VERSION "HIPBNNNYNNNNNNNNNNNNNNNNNNNNNNNNNNNNNNNNNN/4/%%/4/'%**4NNN///"

NS_ :

BS_:

BU_: EXXOTEST__XXX

BO_ 2565799678 ACL: 8 EXXOTEST__XXX
 SG_ ArbitraryAddressCapable : 63|1@1+ (1,0) [0|1] ""  EXXOTEST__XXX
 SG_ IndustryGroup M : 60|3@1+ (1,0) [0|7] ""  EXXOTEST__XXX
 SG_ VehicleSystemInstance : 56|4@1+ (1,0) [0|15] ""  EXXOTEST__XXX
 SG_ Function : 40|8@1+ (1,0) [0|255] ""  EXXOTEST__XXX
 SG_ FunctionInstance : 35|5@1+ (1,0) [0|31] ""  EXXOTEST__XXX
 SG_ ECUInstance : 32|3@1+ (1,0) [0|7] ""  EXXOTEST__XXX
 SG_ ManufacturerCode : 21|11@1+ (1,0) [0|2047] ""  EXXOTEST__XXX
 SG_ IdentityNumber : 0|21@1+ (1,0) [0|2097152] ""  EXXOTEST__XXX
 SG_ VehicleSystem m0 : 49|7@1+ (1,0) [0|127] ""  EXXOTEST__XXX
 SG_ VehicleSystem5 m5 : 49|7@1+ (1,0) [0|127] ""  EXXOTEST__XXX
 SG_ VehicleSystem4 m4 : 49|7@1+ (1,0) [0|127] ""  EXXOTEST__XXX
 SG_ VehicleSystem3 m3 : 49|7@1+ (1,0) [0|127] ""  EXXOTEST__XXX
 SG_ VehicleSystem2 m2 : 49|7@1+ (1,0) [0|127] ""  EXXOTEST__XXX
 SG_ VehicleSystem1 m1 : 49|7@1+ (1,0) [0|127] ""  EXXOTEST__XXX

BO_ 2632711934 TPDT: 8 EXXOTEST__XXX
 SG_ SequenceNumber : 0|8@1+ (1,0) [0|255] ""  EXXOTEST__XXX

BO_ 2632777470 TPCM: 8 EXXOTEST__XXX
 SG_ TotalNumberOfPacketsEoMA m19 : 24|8@1+ (1,0) [0|255] ""  EXXOTEST__XXX
 SG_ TotalMessageSizeEoMA m19 : 8|16@1+ (1,0) [0|64255] "counts"  EXXOTEST__XXX
 SG_ TotalMessageSizeBAM m32 : 8|16@1+ (1,0) [0|64255] "counts"  EXXOTEST__XXX
 SG_ TotalNumberOfPacketsBAM m32 : 24|8@1+ (1,0) [0|255] ""  EXXOTEST__XXX
 SG_ ConnectionAbortReason m255 : 8|8@1+ (1,0) [0|255] ""  EXXOTEST__XXX
 SG_ NextPacketNumberToBeSent m17 : 16|8@1+ (1,0) [0|255] ""  EXXOTEST__XXX
 SG_ NumberOfPacketsThatCanBeSent m17 : 8|8@1+ (1,0) [0|255] ""  EXXOTEST__XXX
 SG_ PGNumber : 40|24@1+ (1,0) [0|16777200] ""  EXXOTEST__XXX
 SG_ MaximumNumberOfPackets m16 : 32|8@1+ (1,0) [0|255] ""  EXXOTEST__XXX
 SG_ TotalNumberOfPackets m16 : 24|8@1+ (1,0) [0|255] ""  EXXOTEST__XXX
 SG_ TotalMessageSize m16 : 8|16@1+ (1,0) [0|64255] "counts"  EXXOTEST__XXX
 SG_ ControlByte M : 0|8@1+ (1,0) [0|255] ""  EXXOTEST__XXX

BO_ 2565537534 RQST: 3 EXXOTEST__XXX
 SG_ ParameterGroupNumber : 0|24@1+ (1,0) [0|16777215] ""  EXXOTEST__XXX

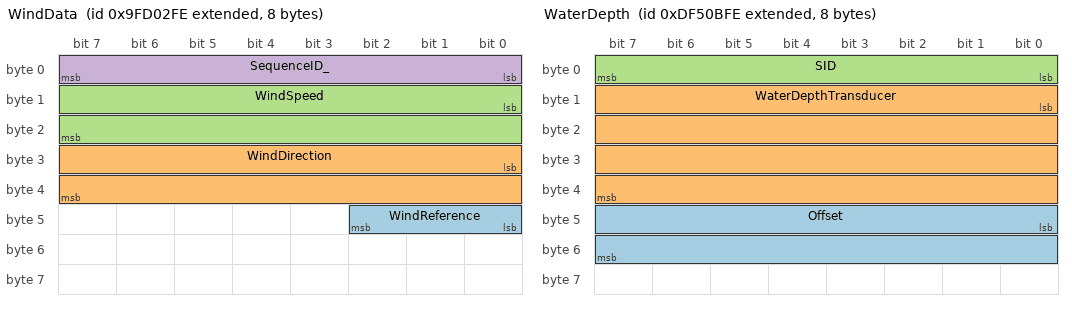
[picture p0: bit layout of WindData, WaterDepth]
BO_ 2315059966 WindData: 8 EXXOTEST__XXX
 SG_ WindReference : 40|3@1+ (1,0) [0|7] ""  EXXOTEST__XXX
 SG_ WindDirection : 24|16@1+ (0.0001,0) [0|6.28318] "rad"  EXXOTEST__XXX
 SG_ WindSpeed : 8|16@1+ (0.01,0) [0|655.32] "m/s"  EXXOTEST__XXX
 SG_ SequenceID_ : 0|8@1+ (1,0) [0|252] ""  EXXOTEST__XXX

BO_ 2381646846 WaterDepth: 8 EXXOTEST__XXX
 SG_ Offset : 40|16@1- (0.001,0) [-32.764|32.764] "m"  EXXOTEST__XXX
 SG_ WaterDepthTransducer : 8|32@1+ (0.01,0) [0|42950000] "m"  EXXOTEST__XXX
 SG_ SID : 0|8@1+ (1,0) [0|252] ""  EXXOTEST__XXX

BO_ 2315129598 VesselSpeedComponents: 12 EXXOTEST__XXX
 SG_ SternSpeedGroundreferenced : 80|16@1- (0.001,0) [-32.764|32.764] "m/s"  EXXOTEST__XXX
 SG_ SternSpeedWaterreferenced : 64|16@1- (0.001,0) [-32.764|32.764] "m/s"  EXXOTEST__XXX
 SG_ TransverseSpeedGroundreferenced : 48|16@1- (0.001,0) [-32.764|32.764] "m/s"  EXXOTEST__XXX
 SG_ LngtudinalSpeedGroundreferenced : 32|16@1- (0.001,0) [-32.764|32.764] "m/s"  EXXOTEST__XXX
 SG_ TransverseSpeedWaterreferenced : 16|16@1- (0.001,0) [-32.764|32.764] "m/s"  EXXOTEST__XXX
 SG_ LngitudinalSpeedWaterreferenced : 0|16@1- (0.001,0) [-32.764|32.764] "m/s"  EXXOTEST__XXX

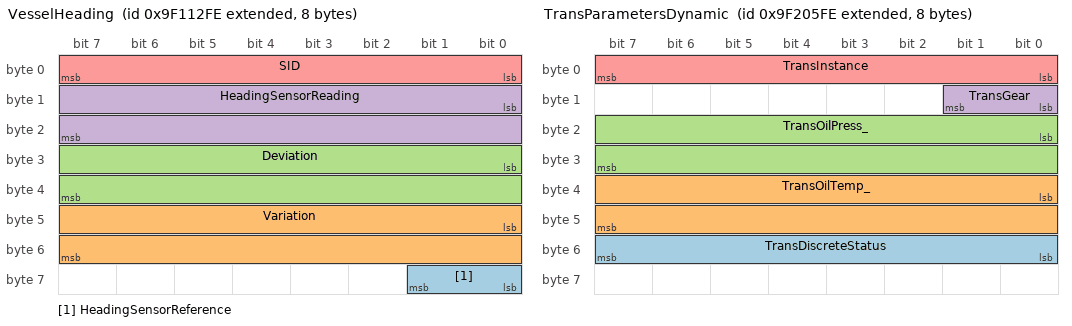
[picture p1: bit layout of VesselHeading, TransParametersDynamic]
BO_ 2314277630 VesselHeading: 8 EXXOTEST__XXX
 SG_ HeadingSensorReference : 56|2@1+ (1,0) [0|3] ""  EXXOTEST__XXX
 SG_ Variation : 40|16@1- (0.0001,0) [-3.14159|3.14159] "rad"  EXXOTEST__XXX
 SG_ Deviation : 24|16@1- (0.0001,0) [-3.14159|3.14159] "rad"  EXXOTEST__XXX
 SG_ HeadingSensorReading : 8|16@1+ (0.0001,0) [0|6.28318] "rad"  EXXOTEST__XXX
 SG_ SID : 0|8@1+ (1,0) [0|252] ""  EXXOTEST__XXX

BO_ 2583172606 UserDatumSettings: 40 EXXOTEST__XXX

BO_ 2515667198 TripParametersVessel: 14 EXXOTEST__XXX
 SG_ TripRunTime : 80|32@1+ (0.001,0) [0|4295000] "sec"  EXXOTEST__XXX
 SG_ EstFuelRemaining : 64|16@1+ (0.001,0) [0|65.532] "cu_m"  EXXOTEST__XXX
 SG_ DistanceToEmpty : 32|32@1+ (0.01,0) [0|42950000] "m"  EXXOTEST__XXX
 SG_ TimeToEmpty : 0|32@1+ (0.001,0) [0|4295000] "sec"  EXXOTEST__XXX

BO_ 2515667454 TripParametersEng: 9 EXXOTEST__XXX
 SG_ InstantaneousFuelEconomy : 56|16@1- (0.0001,0) [-3.2764|3.2764] "cu_m/hr"  EXXOTEST__XXX
 SG_ FuelRateEconomy : 40|16@1- (0.0001,0) [-3.2764|3.2764] "cu_m/hr"  EXXOTEST__XXX
 SG_ FuelRateAverage : 24|16@1- (0.0001,0) [-3.2764|3.2764] "cu_m/hr"  EXXOTEST__XXX
 SG_ TripFuelUsed : 8|16@1+ (0.001,0) [0|65.532] "cu_m"  EXXOTEST__XXX
 SG_ EngInstance : 0|8@1+ (1,0) [0|255] ""  EXXOTEST__XXX

BO_ 2314339838 TransParametersDynamic: 8 EXXOTEST__XXX
 SG_ TransDiscreteStatus : 48|8@1+ (1,0) [0|255] ""  EXXOTEST__XXX
 SG_ TransOilTemp_ : 32|16@1+ (0.1,0) [0|6553.2] "°K"  EXXOTEST__XXX
 SG_ TransOilPress_ : 16|16@1+ (100,0) [0|6553200] "Pa"  EXXOTEST__XXX
 SG_ TransGear : 8|2@1+ (1,0) [0|3] ""  EXXOTEST__XXX
 SG_ TransInstance : 0|8@1+ (1,0) [0|255] ""  EXXOTEST__XXX

BO_ 2314602750 TrackedTargetData: 28 EXXOTEST__XXX
 SG_ CPA : 112|32@1- (0.01,0) [-21470000|21470000] "m"  EXXOTEST__XXX
 SG_ Speed : 96|16@1+ (0.01,0) [0|655.32] "m/s"  EXXOTEST__XXX
 SG_ Course : 80|16@1+ (0.0001,0) [0|6.28318] "rad"  EXXOTEST__XXX
 SG_ Distance : 48|32@1- (0.01,0) [-21470000|21470000] "m"  EXXOTEST__XXX
 SG_ Bearing : 32|16@1+ (0.0001,0) [0|6.28318] "rad"  EXXOTEST__XXX
 SG_ BearingReference : 28|2@1+ (1,0) [0|3] ""  EXXOTEST__XXX
 SG_ TrackStatus : 24|4@1+ (1,0) [0|15] ""  EXXOTEST__XXX
 SG_ TargetID : 8|16@1+ (1,0) [0|65532] ""  EXXOTEST__XXX
 SG_ SequenceID_ : 0|8@1+ (1,0) [0|252] ""  EXXOTEST__XXX
 SG_ Name : 208|16@1+ (1,0) [0|255] ""  EXXOTEST__XXX
 SG_ UTCOfFix : 176|32@1+ (0.0001,0) [0|86401] "sec"  EXXOTEST__XXX
 SG_ TCPA : 144|32@1- (0.001,0) [-2148000|2148000] "sec"  EXXOTEST__XXX

BO_ 2650544894 RouteAndWPServiceWPListWPNamePos: 14 EXXOTEST__XXX
 SG_ WPName : 96|16@1+ (1,0) [0|255] "ASCII"  EXXOTEST__XXX
 SG_ WPID : 80|16@1+ (1,0) [0|65532] ""  EXXOTEST__XXX
 SG_ reserved : 64|16@1+ (1,0) [0|65532] ""  EXXOTEST__XXX
 SG_ DatabaseID : 48|16@1+ (1,0) [0|65532] ""  EXXOTEST__XXX
 SG_ NumberOfValidWPsInWPList : 32|16@1+ (1,0) [0|65532] ""  EXXOTEST__XXX
 SG_ nItems : 16|16@1+ (1,0) [0|65532] ""  EXXOTEST__XXX
 SG_ StartWPID : 0|16@1+ (1,0) [0|65532] ""  EXXOTEST__XXX

BO_ 2650544382 RouteAndWPServiceDatabaseComment: 11 EXXOTEST__XXX
 SG_ CommentText : 64|24@1+ (1,0) [0|255] ""  EXXOTEST__XXX
 SG_ DatabaseID : 48|16@1+ (1,0) [0|65532] ""  EXXOTEST__XXX
 SG_ NumberOfDatabasesWithComments : 32|16@1+ (1,0) [0|65532] ""  EXXOTEST__XXX
 SG_ nItems : 16|16@1+ (1,0) [0|65532] ""  EXXOTEST__XXX
 SG_ StartDatabaseID : 0|16@1+ (1,0) [0|65532] ""  EXXOTEST__XXX

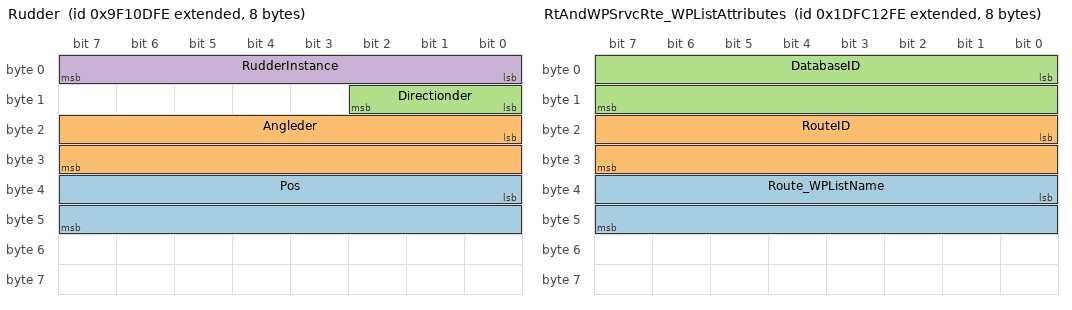
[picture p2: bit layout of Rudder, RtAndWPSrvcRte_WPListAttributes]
BO_ 2314276350 Rudder: 8 EXXOTEST__XXX
 SG_ Pos : 32|16@1- (0.0001,0) [-3.14159|3.14159] "rad"  EXXOTEST__XXX
 SG_ Angleder : 16|16@1- (0.0001,0) [-3.14159|3.14159] "rad"  EXXOTEST__XXX
 SG_ Directionder : 8|3@1+ (1,0) [0|7] ""  EXXOTEST__XXX
 SG_ RudderInstance : 0|8@1+ (1,0) [0|255] ""  EXXOTEST__XXX

BO_ 2650543614 RtAndWPSrvcXTELmtNvgationMethod: 15 EXXOTEST__XXX
 SG_ NavMethodInLegAfterWP : 112|2@1+ (1,0) [0|3] ""  EXXOTEST__XXX
 SG_ XTELimitInLegAfterWP : 96|16@1- (1,0) [-32764|32764] "m"  EXXOTEST__XXX
 SG_ RPS : 80|16@1+ (1,0) [0|65532] ""  EXXOTEST__XXX
 SG_ RouteID : 64|16@1+ (1,0) [0|65532] ""  EXXOTEST__XXX
 SG_ DatabaseID : 48|16@1+ (1,0) [0|65532] ""  EXXOTEST__XXX
 SG_ NmbrOfWypntsWthASpcfcXTELmtNvMth : 32|16@1+ (1,0) [0|65532] ""  EXXOTEST__XXX
 SG_ nItems : 16|16@1+ (1,0) [0|65532] ""  EXXOTEST__XXX
 SG_ StartRPS : 0|16@1+ (1,0) [0|65532] ""  EXXOTEST__XXX

BO_ 2650542846 RtAndWPSrvcRte_WPListAttributes: 8 EXXOTEST__XXX
 SG_ Route_WPListName : 32|16@1+ (1,0) [0|255] "ASCII"  EXXOTEST__XXX
 SG_ RouteID : 16|16@1+ (1,0) [0|65532] ""  EXXOTEST__XXX
 SG_ DatabaseID : 0|16@1+ (1,0) [0|65532] ""  EXXOTEST__XXX

BO_ 2650543870 RouteAndWPServiceWPComment: 15 EXXOTEST__XXX
 SG_ Comment : 96|24@1+ (1,0) [0|255] ""  EXXOTEST__XXX
 SG_ WPID_RPS : 80|16@1+ (1,0) [0|65532] ""  EXXOTEST__XXX
 SG_ RouteID : 64|16@1+ (1,0) [0|65532] ""  EXXOTEST__XXX
 SG_ DatabaseID : 48|16@1+ (1,0) [0|65532] ""  EXXOTEST__XXX
 SG_ NumberOfWPsWithComments : 32|16@1+ (1,0) [0|65532] ""  EXXOTEST__XXX
 SG_ nItems : 16|16@1+ (1,0) [0|65532] ""  EXXOTEST__XXX
 SG_ StartID : 0|16@1+ (1,0) [0|65532] ""  EXXOTEST__XXX

BO_ 2583300606 GNSSRAIMOutput: 15 EXXOTEST__XXX
 SG_ StdDeviationOfBias : 104|16@1- (0.01,0) [-327.64|327.64] "m"  EXXOTEST__XXX
 SG_ EstimateOfPseudorangeBias : 88|16@1- (0.01,0) [-327.64|327.64] "m"  EXXOTEST__XXX
 SG_ ProbabilityOfMissedDetection : 72|8@1- (1,0) [-124|124] "%"  EXXOTEST__XXX
 SG_ SVIDOfMostLikelyFailedSat : 64|8@1+ (1,0) [0|252] ""  EXXOTEST__XXX
 SG_ AltitudeExpectedError : 48|16@1- (0.01,0) [-327.64|327.64] "m"  EXXOTEST__XXX
 SG_ LongitudeExpectedError : 32|16@1- (0.01,0) [-327.64|327.64] "m"  EXXOTEST__XXX
 SG_ LatitudeExpectedError : 16|16@1- (0.01,0) [-327.64|327.64] "m"  EXXOTEST__XXX
 SG_ IntegrityFlag : 8|2@1+ (1,0) [0|3] ""  EXXOTEST__XXX
 SG_ SequenceID_ : 0|8@1+ (1,0) [0|252] ""  EXXOTEST__XXX

BO_ 2583299838 GNSSPseudorangeNoiseStatistics: 15 EXXOTEST__XXX
 SG_ STDOfAltError : 104|16@1+ (0.01,0) [0|655.32] "m"  EXXOTEST__XXX
 SG_ STDOfLonError : 88|16@1+ (0.01,0) [0|655.32] "m"  EXXOTEST__XXX
 SG_ STDOfLatError : 72|16@1+ (0.01,0) [0|655.32] "m"  EXXOTEST__XXX
 SG_ OrientationOfMajorAxis : 56|16@1+ (0.0001,0) [0|6.28318] "rad"  EXXOTEST__XXX
 SG_ STDOfMinorAxis : 40|16@1+ (0.01,0) [0|655.32] "m"  EXXOTEST__XXX
 SG_ STDOfMajorAxis : 24|16@1+ (0.01,0) [0|655.32] "m"  EXXOTEST__XXX
 SG_ RMSOfPosUncertainty : 8|16@1+ (0.01,0) [0|655.32] "m"  EXXOTEST__XXX
 SG_ SID : 0|8@1+ (1,0) [0|252] ""  EXXOTEST__XXX

BO_ 2583301118 GNSSPseudorangeErrorStatistics: 15 EXXOTEST__XXX
 SG_ StdDevAltitudeError : 104|16@1+ (0.01,0) [0|655.32] "m"  EXXOTEST__XXX
 SG_ StdDevLongitudeError : 88|16@1+ (0.01,0) [0|655.32] "m"  EXXOTEST__XXX
 SG_ StdDevLatitudeError : 72|16@1+ (0.01,0) [0|655.32] "m"  EXXOTEST__XXX
 SG_ OrientationOfErrorEllipse : 56|16@1+ (0.0001,0) [0|6.28318] "rad"  EXXOTEST__XXX
 SG_ StdDevMinorErrorEllipse : 40|16@1+ (0.01,0) [0|655.32] "m"  EXXOTEST__XXX
 SG_ StdDevMajorErrorEllipse : 24|16@1+ (0.01,0) [0|655.32] "m"  EXXOTEST__XXX
 SG_ RMSStdDevOfRangeInputs : 8|16@1+ (0.01,0) [0|655.32] "m"  EXXOTEST__XXX
 SG_ SequenceID_ : 0|8@1+ (1,0) [0|252] ""  EXXOTEST__XXX

BO_ 2381841918 GNSSPosData: 51 EXXOTEST__XXX
 SG_ AgeOfDGNSSReferenceStationN : 392|16@1+ (0.01,0) [0|655.32] "sec"  EXXOTEST__XXX
 SG_ ReferenceStationIDN : 380|12@1+ (1,0) [0|4095] ""  EXXOTEST__XXX
 SG_ ReferenceStationTypeN : 376|4@1+ (1,0) [0|15] ""  EXXOTEST__XXX
 SG_ AgeOfDGNSSCorrections1_ : 360|16@1+ (0.01,0) [0|655.32] "sec"  EXXOTEST__XXX
 SG_ ReferenceStationID1_ : 348|12@1+ (1,0) [0|4095] ""  EXXOTEST__XXX
 SG_ ReferenceStationType1 : 344|4@1+ (1,0) [0|15] ""  EXXOTEST__XXX
 SG_ NumberOfReferenceStations_ : 336|8@1+ (1,0) [0|252] ""  EXXOTEST__XXX
 SG_ GeoidalSeparation_ : 304|32@1- (0.01,0) [-21470000|21470000] "m"  EXXOTEST__XXX
 SG_ PDOP_ : 288|16@1- (0.01,0) [-327.64|327.64] ""  EXXOTEST__XXX
 SG_ HDOP_ : 272|16@1- (0.01,0) [-327.64|327.64] ""  EXXOTEST__XXX
 SG_ NumberOfSVs_ : 264|8@1+ (1,0) [0|252] ""  EXXOTEST__XXX
 SG_ Integrity : 256|2@1+ (1,0) [0|3] ""  EXXOTEST__XXX
 SG_ MethodGNSS : 252|4@1+ (1,0) [0|15] ""  EXXOTEST__XXX
 SG_ TypeOfSystem_ : 248|4@1+ (1,0) [0|15] ""  EXXOTEST__XXX
 SG_ Altitude_high : 216|32@1- (4294.967296,0) [-9223000000000|9223000000000] "m"  EXXOTEST__XXX
 SG_ Altitude_low : 184|32@1+ (1E-06,0) [0|4294.967295] "m"  EXXOTEST__XXX
 SG_ Longitude_high : 152|32@1- (1,0) [-180|180] "deg"  EXXOTEST__XXX
 SG_ Longitude_low : 120|32@1+ (1,0) [0|0] "deg"  EXXOTEST__XXX
 SG_ Latitude_high : 88|32@1- (1,0) [-90|90] "deg"  EXXOTEST__XXX
 SG_ Latitude_low : 56|32@1+ (1,0) [0|0] "deg"  EXXOTEST__XXX
 SG_ PosTime : 24|32@1+ (0.0001,0) [0|86401] "sec"  EXXOTEST__XXX
 SG_ PosDate : 8|16@1+ (1,0) [0|65532] "day"  EXXOTEST__XXX
 SG_ SID : 0|8@1+ (1,0) [0|252] ""  EXXOTEST__XXX

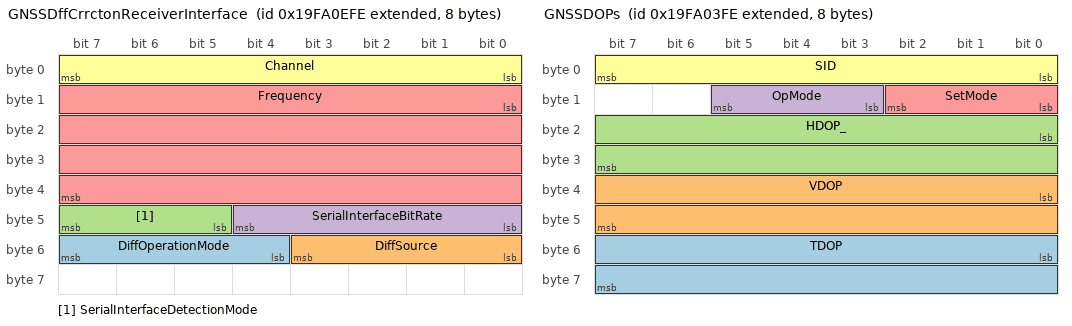
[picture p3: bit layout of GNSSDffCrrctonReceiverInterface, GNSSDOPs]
BO_ 2583301886 GNSSDffCrrctonReceiverInterface: 8 EXXOTEST__XXX
 SG_ DiffOperationMode : 52|4@1+ (1,0) [0|15] ""  EXXOTEST__XXX
 SG_ DiffSource : 48|4@1+ (1,0) [0|15] ""  EXXOTEST__XXX
 SG_ SerialInterfaceDetectionMode : 45|3@1+ (1,0) [0|7] ""  EXXOTEST__XXX
 SG_ SerialInterfaceBitRate : 40|5@1+ (1,0) [0|31] ""  EXXOTEST__XXX
 SG_ Frequency : 8|32@1+ (10,0) [0|327040] "Hz"  EXXOTEST__XXX
 SG_ Channel : 0|8@1+ (1,0) [0|252] ""  EXXOTEST__XXX

BO_ 2583302142 GNSSDffCorrectionReceiverSignal: 21 EXXOTEST__XXX
 SG_ SatelliteServiceIDNo : 147|16@1+ (1,0) [0|65535] ""  EXXOTEST__XXX
 SG_ TimeSinceLastSatDiffSync : 131|16@1+ (0.01,0) [0|655.32] "sec"  EXXOTEST__XXX
 SG_ DiffSource : 127|4@1+ (1,0) [0|15] ""  EXXOTEST__XXX
 SG_ UsedAsCorrectionSource : 123|2@1+ (1,0) [0|3] ""  EXXOTEST__XXX
 SG_ DiffSignalDetectionMode : 117|6@1+ (1,0) [0|63] ""  EXXOTEST__XXX
 SG_ DiffSignalBitRate : 112|5@1+ (1,0) [0|31] ""  EXXOTEST__XXX
 SG_ StationID : 100|12@1+ (1,0) [0|4095] ""  EXXOTEST__XXX
 SG_ StationType : 96|4@1+ (1,0) [0|15] ""  EXXOTEST__XXX
 SG_ Frequency : 64|32@1+ (10,0) [0|327040] "Hz"  EXXOTEST__XXX
 SG_ SignalSNR : 48|16@1- (0.01,0) [-327.64|327.64] "dB"  EXXOTEST__XXX
 SG_ SignalStrength : 16|32@1- (0.01,0) [-327.64|327.64] "dB_re_uV/m"  EXXOTEST__XXX
 SG_ Channel : 8|8@1+ (1,0) [0|252] ""  EXXOTEST__XXX
 SG_ SID : 0|8@1+ (1,0) [0|252] ""  EXXOTEST__XXX

BO_ 2583299070 GNSSDOPs: 8 EXXOTEST__XXX
 SG_ TDOP : 48|16@1- (0.01,0) [-327.64|327.64] ""  EXXOTEST__XXX
 SG_ VDOP : 32|16@1- (0.01,0) [-327.64|327.64] ""  EXXOTEST__XXX
 SG_ HDOP_ : 16|16@1- (0.01,0) [-327.64|327.64] ""  EXXOTEST__XXX
 SG_ OpMode : 11|3@1+ (1,0) [0|7] ""  EXXOTEST__XXX
 SG_ SetMode : 8|3@1+ (1,0) [0|7] ""  EXXOTEST__XXX
 SG_ SID : 0|8@1+ (1,0) [0|252] ""  EXXOTEST__XXX

BO_ 2583298814 GNSSCtrlStatus: 16 EXXOTEST__XXX
 SG_ UseAntennaAltitudeFor2DMode : 120|2@1+ (1,0) [0|3] ""  EXXOTEST__XXX
 SG_ AntennaAltitudeFor2DMode : 88|32@1- (0.01,0) [-21470000|21470000] "m"  EXXOTEST__XXX
 SG_ MaxCorrectionAge : 72|16@1+ (0.01,0) [0|655.32] "sec"  EXXOTEST__XXX
 SG_ Pos_VelocityFilter : 70|2@1+ (1,0) [0|3] ""  EXXOTEST__XXX
 SG_ DGNSSMode : 67|3@1+ (1,0) [0|7] ""  EXXOTEST__XXX
 SG_ GNSSMode : 64|3@1+ (1,0) [0|7] ""  EXXOTEST__XXX
 SG_ SNRMask : 48|16@1- (0.01,0) [-327.64|327.64] "dB"  EXXOTEST__XXX
 SG_ PDOPSwitch : 32|16@1- (0.01,0) [-327.64|327.64] ""  EXXOTEST__XXX
 SG_ PDOPMask : 16|16@1- (0.01,0) [-327.64|327.64] ""  EXXOTEST__XXX
 SG_ SVElevationMask : 0|16@1- (0.0001,0) [-3.14159|3.14159] "rad"  EXXOTEST__XXX

BO_ 2583303422 GLONASSAlmanacData: 26 EXXOTEST__XXX
 SG_ tnA2 : 196|12@1+ (1,0) [0|4095] ""  EXXOTEST__XXX
 SG_ tcA : 168|28@1+ (1,0) [0|268435455] ""  EXXOTEST__XXX
 SG_ inA : 144|24@1+ (1,0) [0|16777215] ""  EXXOTEST__XXX
 SG_ nA3 : 120|24@1+ (1,0) [0|16777215] ""  EXXOTEST__XXX
 SG_ tnA : 96|24@1+ (1,0) [0|16777215] ""  EXXOTEST__XXX
 SG_ TnA : 72|24@1+ (1,0) [0|16777215] ""  EXXOTEST__XXX
 SG_ nA2 : 56|16@1+ (1,0) [0|65535] ""  EXXOTEST__XXX
 SG_ DOT : 48|8@1+ (1,0) [0|255] ""  EXXOTEST__XXX
 SG_ nA : 32|16@1+ (1,0) [0|65535] ""  EXXOTEST__XXX
 SG_ HnA : 27|5@1+ (1,0) [0|31] ""  EXXOTEST__XXX
 SG_ CnA : 26|1@1+ (1,0) [0|1] ""  EXXOTEST__XXX
 SG_ NA : 8|16@1+ (1,0) [0|65532] ""  EXXOTEST__XXX
 SG_ PRN : 0|8@1+ (1,0) [0|252] ""  EXXOTEST__XXX

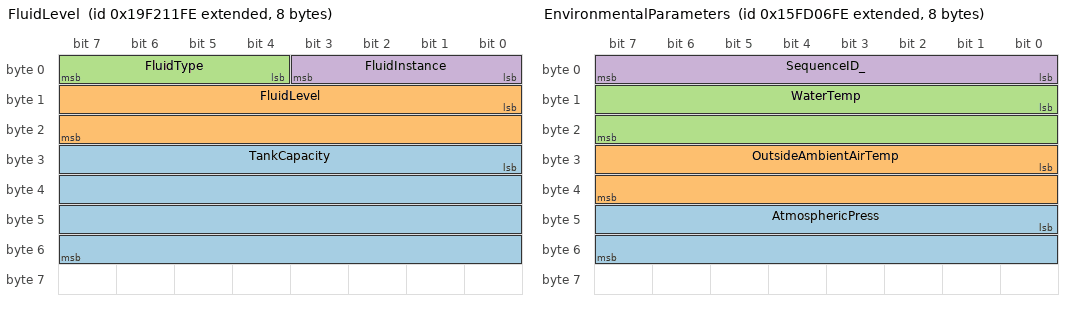
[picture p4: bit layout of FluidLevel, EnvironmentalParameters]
BO_ 2582778366 FluidLevel: 8 EXXOTEST__XXX
 SG_ TankCapacity : 24|32@1+ (0.0001,0) [0|429600] "cu_m"  EXXOTEST__XXX
 SG_ FluidLevel : 8|16@1- (1,0) [-124|124] ""  EXXOTEST__XXX
 SG_ FluidType : 4|4@1+ (1,0) [0|15] ""  EXXOTEST__XXX
 SG_ FluidInstance : 0|4@1+ (1,0) [0|15] ""  EXXOTEST__XXX

BO_ 2516387582 EnvironmentalParameters: 8 EXXOTEST__XXX
 SG_ AtmosphericPress : 40|16@1+ (100,0) [0|6553200] "Pa"  EXXOTEST__XXX
 SG_ OutsideAmbientAirTemp : 24|16@1+ (0.01,0) [0|655.32] "°K"  EXXOTEST__XXX
 SG_ WaterTemp : 8|16@1+ (0.01,0) [0|655.32] "°K"  EXXOTEST__XXX
 SG_ SequenceID_ : 0|8@1+ (1,0) [0|252] ""  EXXOTEST__XXX

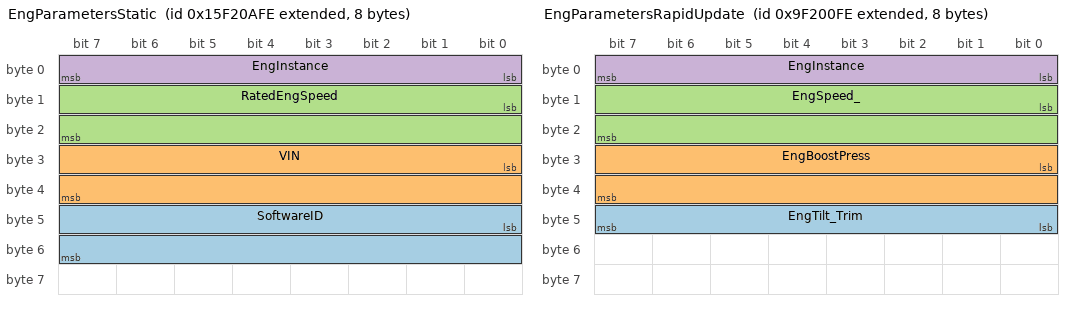
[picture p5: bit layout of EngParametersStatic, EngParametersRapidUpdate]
BO_ 2515667710 EngParametersStatic: 8 EXXOTEST__XXX
 SG_ SoftwareID : 40|16@1+ (1,0) [0|255] "ASCII"  EXXOTEST__XXX
 SG_ VIN : 24|16@1+ (1,0) [0|255] "ASCII"  EXXOTEST__XXX
 SG_ RatedEngSpeed : 8|16@1+ (1,0) [0|16383] "rpm"  EXXOTEST__XXX
 SG_ EngInstance : 0|8@1+ (1,0) [0|255] ""  EXXOTEST__XXX

BO_ 2314338558 EngParametersRapidUpdate: 8 EXXOTEST__XXX
 SG_ EngTilt_Trim : 40|8@1- (1,0) [-124|124] ""  EXXOTEST__XXX
 SG_ EngBoostPress : 24|16@1+ (100,0) [0|6553200] "Pa"  EXXOTEST__XXX
 SG_ EngSpeed_ : 8|16@1+ (1,0) [0|16383] "rpm"  EXXOTEST__XXX
 SG_ EngInstance : 0|8@1+ (1,0) [0|255] ""  EXXOTEST__XXX

BO_ 2314338814 EngParametersDynamic: 26 EXXOTEST__XXX
 SG_ PercentEngTorque : 200|8@1- (1,0) [-124|124] ""  EXXOTEST__XXX
 SG_ PercentEngLoad : 192|8@1- (1,0) [-124|124] ""  EXXOTEST__XXX
 SG_ EngDiscreteStatus2 : 176|16@1+ (1,0) [0|65535] ""  EXXOTEST__XXX
 SG_ EngDiscreteStatus1 : 160|16@1+ (1,0) [0|65535] ""  EXXOTEST__XXX
 SG_ FuelPress : 136|16@1+ (1000,0) [0|65532000] "Pa"  EXXOTEST__XXX
 SG_ EngCoolantPress_ : 120|16@1+ (100,0) [0|6553200] "Pa"  EXXOTEST__XXX
 SG_ TotalEngHours : 88|32@1+ (1,0) [0|32704] "sec"  EXXOTEST__XXX
 SG_ FuelRate : 72|16@1- (0.0001,0) [-3.2764|3.2764] "cu_m/hr"  EXXOTEST__XXX
 SG_ AltPotential : 56|16@1- (0.01,0) [-327.64|327.64] "V"  EXXOTEST__XXX
 SG_ EngTemp : 40|16@1+ (0.01,0) [0|655.32] "°K"  EXXOTEST__XXX
 SG_ EngOilTemp : 24|16@1+ (0.1,0) [0|6553.2] "°K"  EXXOTEST__XXX
 SG_ EngOilPress_ : 8|16@1+ (100,0) [0|6553200] "Pa"  EXXOTEST__XXX
 SG_ EngInstance : 0|8@1+ (1,0) [0|255] ""  EXXOTEST__XXX

BO_ 2582975486 DistanceLog: 14 EXXOTEST__XXX
 SG_ DistanceSinceLastReset : 80|32@1+ (1,0) [0|32704] "m"  EXXOTEST__XXX
 SG_ TotalCumulativeDistance : 48|32@1+ (1,0) [0|32704] "m"  EXXOTEST__XXX
 SG_ MeasurementTime : 16|32@1+ (0.0001,0) [0|86401] "sec"  EXXOTEST__XXX
 SG_ MeasurementDate : 0|16@1+ (1,0) [0|65532] "day"  EXXOTEST__XXX

BO_ 2448953086 AISClassAPosReport: 27 EXXOTEST__XXX
 SG_ NavigationalStatus : 200|4@1+ (1,0) [0|15] ""  EXXOTEST__XXX
 SG_ RateOfTurn : 184|16@1- (1,0) [-32768|32767] "rad/s"  EXXOTEST__XXX
 SG_ TrueHeading : 168|16@1+ (0.0001,0) [0|6.28318] "rad"  EXXOTEST__XXX
 SG_ AISTransceiverInformation : 163|5@1+ (1,0) [0|31] ""  EXXOTEST__XXX
 SG_ CommunicationState : 144|19@1+ (1,0) [0|524287] ""  EXXOTEST__XXX
 SG_ SOG : 128|16@1+ (0.01,0) [0|655.32] "m/s"  EXXOTEST__XXX
 SG_ COG : 112|16@1+ (0.0001,0) [0|6.28318] "rad"  EXXOTEST__XXX
 SG_ TimeStamp : 106|6@1+ (1,0) [0|63] ""  EXXOTEST__XXX
 SG_ RAIMflag : 105|1@1+ (1,0) [0|1] ""  EXXOTEST__XXX
 SG_ PosAccuracy : 104|1@1+ (1,0) [0|1] ""  EXXOTEST__XXX
 SG_ Latitude_ : 72|32@1- (1,0) [-90|90] "deg"  EXXOTEST__XXX
 SG_ Longitude_ : 40|32@1- (1,0) [-180|180] "deg"  EXXOTEST__XXX
 SG_ UserID : 8|32@1+ (1,0) [0|4294967292] ""  EXXOTEST__XXX
 SG_ RepeatIndicator : 6|2@1+ (1,0) [0|3] ""  EXXOTEST__XXX
 SG_ MsgID : 0|6@1+ (1,0) [0|63] ""  EXXOTEST__XXX

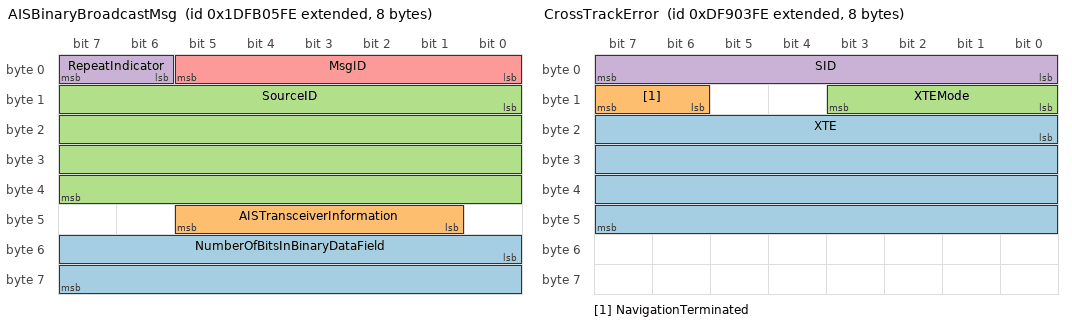
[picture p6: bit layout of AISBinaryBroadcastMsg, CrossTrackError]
BO_ 2650473982 AISBinaryBroadcastMsg: 8 EXXOTEST__XXX
 SG_ NumberOfBitsInBinaryDataField : 48|16@1+ (1,0) [0|65532] ""  EXXOTEST__XXX
 SG_ AISTransceiverInformation : 41|5@1+ (1,0) [0|31] ""  EXXOTEST__XXX
 SG_ SourceID : 8|32@1+ (1,0) [0|4294967292] ""  EXXOTEST__XXX
 SG_ RepeatIndicator : 6|2@1+ (1,0) [0|3] ""  EXXOTEST__XXX
 SG_ MsgID : 0|6@1+ (1,0) [0|63] ""  EXXOTEST__XXX

BO_ 2650475774 AISAssignmentModeCmd: 23 EXXOTEST__XXX
 SG_ IncrementB : 160|16@1+ (1,0) [0|65532] ""  EXXOTEST__XXX
 SG_ OffsetB : 144|16@1+ (1,0) [0|65532] ""  EXXOTEST__XXX
 SG_ DestinationIDB : 112|32@1+ (1,0) [0|4294967292] ""  EXXOTEST__XXX
 SG_ IncrementA : 96|16@1+ (1,0) [0|65532] ""  EXXOTEST__XXX
 SG_ OffsetA : 80|16@1+ (1,0) [0|65532] ""  EXXOTEST__XXX
 SG_ DestinationIDA : 48|32@1+ (1,0) [0|4294967292] ""  EXXOTEST__XXX
 SG_ AISTransceiverInformation : 41|5@1+ (1,0) [0|31] ""  EXXOTEST__XXX
 SG_ SourceID : 8|32@1+ (1,0) [0|4294967292] ""  EXXOTEST__XXX
 SG_ RepeatIndicator : 6|2@1+ (1,0) [0|3] ""  EXXOTEST__XXX
 SG_ MsgID : 0|6@1+ (1,0) [0|63] ""  EXXOTEST__XXX

BO_ 2565406462 ACKM: 8 EXXOTEST__XXX
 SG_ AddressBusy m3 : 32|8@1+ (1,0) [0|255] ""  EXXOTEST__XXX
 SG_ ControlByte M : 0|8@1+ (1,0) [0|255] ""  EXXOTEST__XXX
 SG_ ParameterGroupNumber : 40|24@1+ (1,0) [0|16777215] ""  EXXOTEST__XXX
 SG_ GroupFunctionValue : 8|8@1+ (1,0) [0|255] ""  EXXOTEST__XXX
 SG_ AddressAccessDenied m2 : 32|8@1+ (1,0) [0|255] ""  EXXOTEST__XXX
 SG_ AddressNegativeAcknowledgement m1 : 32|8@1+ (1,0) [0|255] ""  EXXOTEST__XXX
 SG_ AddressAcknowledged m0 : 32|8@1+ (1,0) [0|255] ""  EXXOTEST__XXX

BO_ 2382238206 DirectionData: 14 EXXOTEST__XXX
 SG_ Drift : 96|16@1+ (0.01,0) [0|655.32] "m/s"  EXXOTEST__XXX
 SG_ Set : 80|16@1+ (0.0001,0) [0|6.28318] "rad"  EXXOTEST__XXX
 SG_ SpeedThroughWater : 64|16@1+ (0.01,0) [0|655.32] "m/s"  EXXOTEST__XXX
 SG_ Heading : 48|16@1+ (0.0001,0) [0|6.28318] "rad"  EXXOTEST__XXX
 SG_ SpeedOverGround : 32|16@1+ (0.01,0) [0|655.32] "m/s"  EXXOTEST__XXX
 SG_ CourseOverGround : 16|16@1+ (0.0001,0) [0|6.28318] "rad"  EXXOTEST__XXX
 SG_ SID : 8|8@1+ (1,0) [0|252] ""  EXXOTEST__XXX
 SG_ Set_COG_HeadingRef : 4|2@1+ (1,0) [0|3] ""  EXXOTEST__XXX
 SG_ DataMode : 0|4@1+ (1,0) [0|15] ""  EXXOTEST__XXX

BO_ 2583172350 Datum: 20 EXXOTEST__XXX
 SG_ ReferenceDatum : 128|32@1+ (1,0) [0|255] "ASCII"  EXXOTEST__XXX
 SG_ LocalDatum : 0|32@1+ (1,0) [0|255] "ASCII"  EXXOTEST__XXX

BO_ 2449150206 DSCCallInformation: 68 EXXOTEST__XXX
 SG_ VarNbrOfFldsFld22RepExpFldData : 528|16@1+ (1,0) [0|255] "ASCII"  EXXOTEST__XXX
 SG_ DSCExpansionFieldData : 504|16@1+ (1,0) [0|255] "ASCII"  EXXOTEST__XXX
 SG_ TelephoneNumber : 168|16@1+ (1,0) [0|255] "ASCII"  EXXOTEST__XXX
 SG_ ProposedTxFrequencyChannel : 120|48@1+ (1,0) [0|255] "ASCII"  EXXOTEST__XXX
 SG_ ProposedRxFrequencyChannel : 72|48@1+ (1,0) [0|255] "ASCII"  EXXOTEST__XXX
 SG_ MMSIOfShipInDistress : 280|40@1+ (1,0) [0|255] "ASCII"  EXXOTEST__XXX
 SG_ CallingTxFrequencyChannel : 384|48@1+ (1,0) [0|255] "ASCII"  EXXOTEST__XXX
 SG_ CallingRxFrequencyChannel : 336|48@1+ (1,0) [0|255] "ASCII"  EXXOTEST__XXX
 SG_ DSCMsgAddress : 16|40@1+ (1,0) [0|255] "ASCII"  EXXOTEST__XXX
 SG_ DSCCategorySymbol : 8|8@1+ (1,0) [0|252] ""  EXXOTEST__XXX
 SG_ DSCFormatSymbol : 0|8@1+ (1,0) [0|252] ""  EXXOTEST__XXX

BO_ 2583301630 DGNSSCorrections: 16 EXXOTEST__XXX
 SG_ IOD : 120|8@1+ (1,0) [0|252] ""  EXXOTEST__XXX
 SG_ UDRE : 104|16@1+ (0.01,0) [0|655.32] "m"  EXXOTEST__XXX
 SG_ RRC : 88|16@1- (0.0001,0) [-3.2764|3.2764] "m/s"  EXXOTEST__XXX
 SG_ PRC : 56|32@1- (0.0001,0) [-214700|214700] "m"  EXXOTEST__XXX
 SG_ SatelliteID : 48|8@1+ (1,0) [0|252] ""  EXXOTEST__XXX
 SG_ StationHealth : 40|4@1+ (1,0) [0|15] ""  EXXOTEST__XXX
 SG_ TimeOfCorrections : 24|16@1+ (1,0) [0|6553.2] "sec"  EXXOTEST__XXX
 SG_ ReferenceStationType : 20|4@1+ (1,0) [0|15] ""  EXXOTEST__XXX
 SG_ ReferenceStationID : 8|12@1+ (1,0) [0|4095] ""  EXXOTEST__XXX
 SG_ SequenceID_ : 0|8@1+ (1,0) [0|252] ""  EXXOTEST__XXX

BO_ 2583499518 CurrentStationData: 29 EXXOTEST__XXX
 SG_ StationNameString : 216|16@1+ (1,0) [0|255] "ASCII"  EXXOTEST__XXX
 SG_ StationIDString : 200|16@1+ (1,0) [0|255] "ASCII"  EXXOTEST__XXX
 SG_ WaterTemp : 184|16@1+ (0.01,0) [0|655.32] "°K"  EXXOTEST__XXX
 SG_ CurrentFlowDirection : 168|16@1+ (0.0001,0) [0|6.28318] "rad"  EXXOTEST__XXX
 SG_ CurrentSpeed : 152|16@1+ (0.01,0) [0|655.32] "m/s"  EXXOTEST__XXX
 SG_ MeasurementDepth : 120|32@1+ (0.01,0) [0|42950000] "m"  EXXOTEST__XXX
 SG_ StationLocationLongitude : 88|32@1- (1,0) [-180|180] "deg"  EXXOTEST__XXX
 SG_ StationLocationLatitude : 56|32@1- (1,0) [-90|90] "deg"  EXXOTEST__XXX
 SG_ MeasurementTime : 24|32@1+ (0.0001,0) [0|86401] "sec"  EXXOTEST__XXX
 SG_ MeasurementDate : 8|16@1+ (1,0) [0|65532] "day"  EXXOTEST__XXX
 SG_ State : 4|3@1+ (1,0) [0|7] ""  EXXOTEST__XXX
 SG_ Mode : 0|4@1+ (1,0) [0|15] ""  EXXOTEST__XXX

BO_ 2381906942 CrossTrackError: 8 EXXOTEST__XXX
 SG_ XTE : 16|32@1- (0.01,0) [-21470000|21470000] "m"  EXXOTEST__XXX
 SG_ NavigationTerminated : 14|2@1+ (1,0) [0|3] ""  EXXOTEST__XXX
 SG_ XTEMode : 8|4@1+ (1,0) [0|15] ""  EXXOTEST__XXX
 SG_ SID : 0|8@1+ (1,0) [0|252] ""  EXXOTEST__XXX

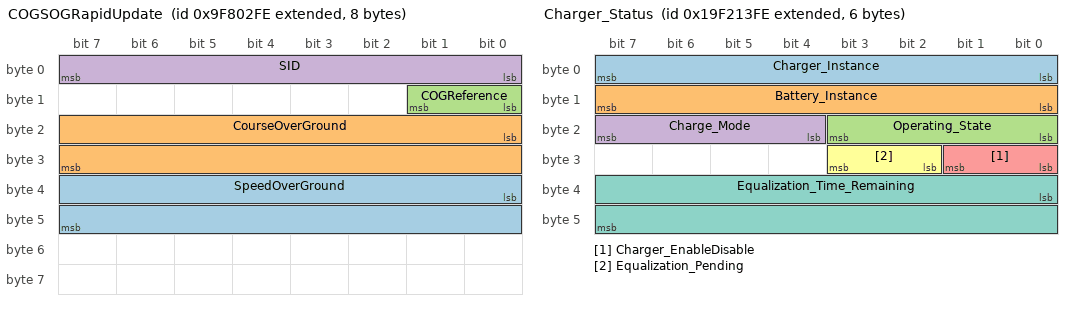
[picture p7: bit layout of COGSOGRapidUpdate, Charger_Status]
BO_ 2314732286 COGSOGRapidUpdate: 8 EXXOTEST__XXX
 SG_ SpeedOverGround : 32|16@1+ (0.01,0) [0|655.32] "m/s"  EXXOTEST__XXX
 SG_ CourseOverGround : 16|16@1+ (0.0001,0) [0|6.28318] "rad"  EXXOTEST__XXX
 SG_ COGReference : 8|2@1+ (1,0) [0|3] ""  EXXOTEST__XXX
 SG_ SID : 0|8@1+ (1,0) [0|252] ""  EXXOTEST__XXX

BO_ 2650475006 AISAddressedSafetyRelatedMsg: 13 EXXOTEST__XXX
 SG_ SafetyRelatedText : 88|16@1+ (1,0) [0|255] ""  EXXOTEST__XXX
 SG_ RetransmitFlag : 86|1@1+ (1,0) [0|1] ""  EXXOTEST__XXX
 SG_ DestinationID : 48|32@1+ (1,0) [0|4294967292] ""  EXXOTEST__XXX
 SG_ SequenceNumber_ : 46|2@1+ (1,0) [0|3] ""  EXXOTEST__XXX
 SG_ AISTransceiverInformation : 41|5@1+ (1,0) [0|31] ""  EXXOTEST__XXX
 SG_ SourceID : 8|32@1+ (1,0) [0|4294967292] ""  EXXOTEST__XXX
 SG_ RepeatIndicator : 6|2@1+ (1,0) [0|3] ""  EXXOTEST__XXX
 SG_ MsgID : 0|6@1+ (1,0) [0|63] ""  EXXOTEST__XXX

BO_ 2650473470 AISAddressedBinaryMsg: 13 EXXOTEST__XXX
 SG_ NumberOfBitsInBinaryDataField : 88|16@1+ (1,0) [0|65532] ""  EXXOTEST__XXX
 SG_ RetransmitFlag : 86|1@1+ (1,0) [0|1] ""  EXXOTEST__XXX
 SG_ DestinationID : 48|32@1+ (1,0) [0|4294967292] ""  EXXOTEST__XXX
 SG_ SequenceNumber_ : 46|2@1+ (1,0) [0|3] ""  EXXOTEST__XXX
 SG_ AISTransceiverInformation : 41|5@1+ (1,0) [0|31] ""  EXXOTEST__XXX
 SG_ SourceID : 8|32@1+ (1,0) [0|4294967292] ""  EXXOTEST__XXX
 SG_ RepeatIndicator : 6|2@1+ (1,0) [0|3] ""  EXXOTEST__XXX
 SG_ MsgID : 0|6@1+ (1,0) [0|63] ""  EXXOTEST__XXX

BO_ 2650473726 AISAcknowledge: 12 EXXOTEST__XXX
 SG_ SequenceNumberForIDn : 94|2@1+ (1,0) [0|3] ""  EXXOTEST__XXX
 SG_ SequenceNumberForID1 : 86|2@1+ (1,0) [0|3] ""  EXXOTEST__XXX
 SG_ DestinationID1 : 48|32@1+ (1,0) [0|4294967292] ""  EXXOTEST__XXX
 SG_ AISTransceiverInformation : 41|5@1+ (1,0) [0|31] ""  EXXOTEST__XXX
 SG_ SourceID : 8|32@1+ (1,0) [0|4294967292] ""  EXXOTEST__XXX
 SG_ RepeatIndicator : 6|2@1+ (1,0) [0|3] ""  EXXOTEST__XXX
 SG_ MsgID : 0|6@1+ (1,0) [0|63] ""  EXXOTEST__XXX

BO_ 2582777854 AC_Input_Status: 20 EXXOTEST__XXX
 SG_ AC_Instance : 0|8@1+ (1,0) [0|252] ""  EXXOTEST__XXX
 SG_ Number_Of_Lines : 8|8@1+ (1,0) [0|252] ""  EXXOTEST__XXX
 SG_ Line : 16|2@1+ (1,0) [0|1] ""  EXXOTEST__XXX
 SG_ Acceptability : 18|2@1+ (1,0) [0|1] ""  EXXOTEST__XXX
 SG_ Voltage : 24|16@1- (0.01,0) [-655.32|655.32] "V"  EXXOTEST__XXX
 SG_ Current : 40|16@1+ (0.1,0) [0|6553.2] "A"  EXXOTEST__XXX
 SG_ Frequency : 56|16@1+ (0.01,0) [0|655.32] "Hz"  EXXOTEST__XXX
 SG_ Breaker_Size : 72|16@1+ (0.1,0) [0|6553.2] "A"  EXXOTEST__XXX
 SG_ Real_Power : 88|32@1+ (1,0) [0|4294967292] "W"  EXXOTEST__XXX
 SG_ Reactive_Power : 120|32@1+ (1,0) [0|4294967292] "VAR"  EXXOTEST__XXX
 SG_ Power_Factor : 152|8@1- (0.01,0) [-1|1] ""  EXXOTEST__XXX

BO_ 2582778110 AC_Output_Status: 20 EXXOTEST__XXX
 SG_ AC_Instance : 0|8@1+ (1,0) [0|252] ""  EXXOTEST__XXX
 SG_ Number_Of_Lines : 8|8@1+ (1,0) [0|252] ""  EXXOTEST__XXX
 SG_ Line : 16|2@1+ (1,0) [0|1] ""  EXXOTEST__XXX
 SG_ Waveform : 18|3@1+ (1,0) [0|1] ""  EXXOTEST__XXX
 SG_ Voltage : 24|16@1- (0.01,0) [-655.32|655.32] "V"  EXXOTEST__XXX
 SG_ Current : 40|16@1+ (0.1,0) [0|6553.2] "A"  EXXOTEST__XXX
 SG_ Frequency : 56|16@1+ (0.01,0) [0|655.32] "Hz"  EXXOTEST__XXX
 SG_ Breaker_Size : 72|16@1+ (0.1,0) [0|6553.2] "A"  EXXOTEST__XXX
 SG_ Real_Power : 88|32@1+ (1,0) [0|4294967292] "W"  EXXOTEST__XXX
 SG_ Reactive_Power : 120|32@1+ (1,0) [0|4294967292] "VAR"  EXXOTEST__XXX
 SG_ Power_Factor : 152|8@1- (0.01,0) [-1|1] ""  EXXOTEST__XXX

BO_ 2582778622 DC_Detailed_Status: 9 EXXOTEST__XXX
 SG_ SID : 0|8@1+ (1,0) [0|252] ""  EXXOTEST__XXX
 SG_ DC_Instance : 8|8@1+ (1,0) [0|252] ""  EXXOTEST__XXX
 SG_ DC_Type : 16|8@1+ (1,0) [0|1] ""  EXXOTEST__XXX
 SG_ State_Of_Charge : 24|8@1+ (1,0) [0|252] "%"  EXXOTEST__XXX
 SG_ State_Of_Health : 32|8@1+ (1,0) [0|252] "%"  EXXOTEST__XXX
 SG_ Time_Remaining : 40|16@1+ (1,0) [0|65532] "minute"  EXXOTEST__XXX
 SG_ Ripple_Voltage : 56|16@1+ (1,0) [0|65] "V"  EXXOTEST__XXX

BO_ 2582778878 Charger_Status: 6 EXXOTEST__XXX
 SG_ Charger_Instance : 0|8@1+ (1,0) [0|252] ""  EXXOTEST__XXX
 SG_ Battery_Instance : 8|8@1+ (1,0) [0|252] ""  EXXOTEST__XXX
 SG_ Operating_State : 16|4@1+ (1,0) [0|1] ""  EXXOTEST__XXX
 SG_ Charge_Mode : 20|4@1+ (1,0) [0|1] ""  EXXOTEST__XXX
 SG_ Charger_EnableDisable : 24|2@1+ (1,0) [0|1] ""  EXXOTEST__XXX
 SG_ Equalization_Pending : 26|2@1+ (1,0) [0|1] ""  EXXOTEST__XXX
 SG_ Equalization_Time_Remaining : 32|16@1+ (1,0) [0|65532] "minute"  EXXOTEST__XXX

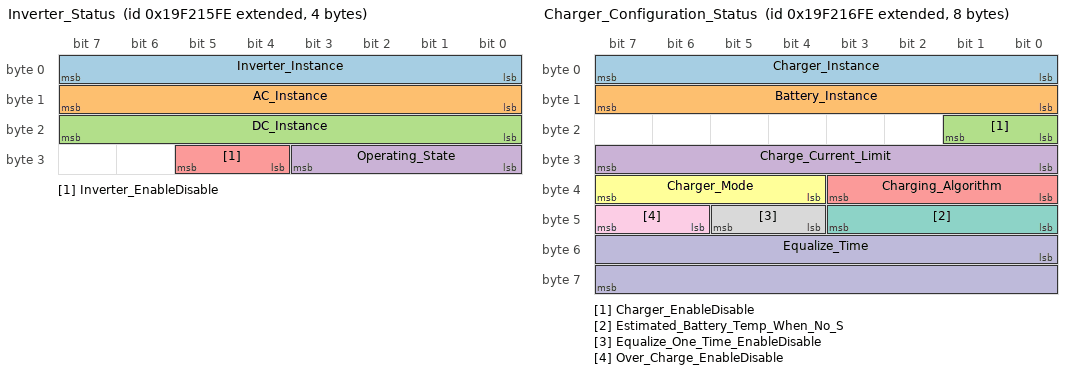
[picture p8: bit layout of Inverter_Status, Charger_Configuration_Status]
BO_ 2582779390 Inverter_Status: 4 EXXOTEST__XXX
 SG_ Inverter_Instance : 0|8@1+ (1,0) [0|252] ""  EXXOTEST__XXX
 SG_ AC_Instance : 8|8@1+ (1,0) [0|252] ""  EXXOTEST__XXX
 SG_ DC_Instance : 16|8@1+ (1,0) [0|252] ""  EXXOTEST__XXX
 SG_ Operating_State : 24|4@1+ (1,0) [0|1] ""  EXXOTEST__XXX
 SG_ Inverter_EnableDisable : 28|2@1+ (1,0) [0|1] ""  EXXOTEST__XXX

BO_ 2582779646 Charger_Configuration_Status: 8 EXXOTEST__XXX
 SG_ Charger_Instance : 0|8@1+ (1,0) [0|252] ""  EXXOTEST__XXX
 SG_ Battery_Instance : 8|8@1+ (1,0) [0|252] ""  EXXOTEST__XXX
 SG_ Charger_EnableDisable : 16|2@1+ (1,0) [0|1] ""  EXXOTEST__XXX
 SG_ Charge_Current_Limit : 24|8@1+ (1,0) [0|252] "%"  EXXOTEST__XXX
 SG_ Charging_Algorithm : 32|4@1+ (1,0) [0|1] ""  EXXOTEST__XXX
 SG_ Charger_Mode : 36|4@1+ (1,0) [0|1] ""  EXXOTEST__XXX
 SG_ Estimated_Battery_Temp_When_No_S : 40|4@1+ (1,0) [0|1] ""  EXXOTEST__XXX
 SG_ Equalize_One_Time_EnableDisable : 44|2@1+ (1,0) [0|1] ""  EXXOTEST__XXX
 SG_ Over_Charge_EnableDisable : 46|2@1+ (1,0) [0|1] ""  EXXOTEST__XXX
 SG_ Equalize_Time : 48|16@1+ (1,0) [0|65532] "minute"  EXXOTEST__XXX

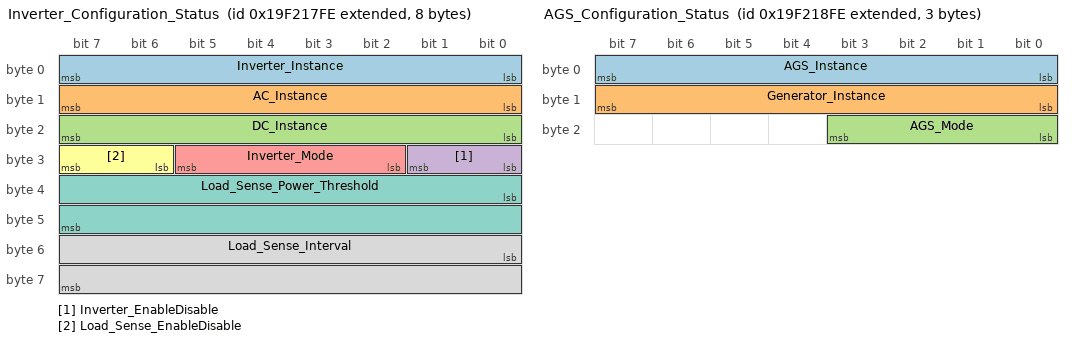
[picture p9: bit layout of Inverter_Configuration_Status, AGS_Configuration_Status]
BO_ 2582779902 Inverter_Configuration_Status: 8 EXXOTEST__XXX
 SG_ Inverter_Instance : 0|8@1+ (1,0) [0|252] ""  EXXOTEST__XXX
 SG_ AC_Instance : 8|8@1+ (1,0) [0|252] ""  EXXOTEST__XXX
 SG_ DC_Instance : 16|8@1+ (1,0) [0|252] ""  EXXOTEST__XXX
 SG_ Inverter_EnableDisable : 24|2@1+ (1,0) [0|1] ""  EXXOTEST__XXX
 SG_ Inverter_Mode : 26|4@1+ (1,0) [0|1] ""  EXXOTEST__XXX
 SG_ Load_Sense_EnableDisable : 30|2@1+ (1,0) [0|1] ""  EXXOTEST__XXX
 SG_ Load_Sense_Power_Threshold : 32|16@1+ (1,0) [0|65532] "W"  EXXOTEST__XXX
 SG_ Load_Sense_Interval : 48|16@1+ (0.01,0) [0|655.32] "s"  EXXOTEST__XXX

BO_ 2582780158 AGS_Configuration_Status: 3 EXXOTEST__XXX
 SG_ AGS_Instance : 0|8@1+ (1,0) [0|252] ""  EXXOTEST__XXX
 SG_ Generator_Instance : 8|8@1+ (1,0) [0|252] ""  EXXOTEST__XXX
 SG_ AGS_Mode : 16|4@1+ (1,0) [0|1] ""  EXXOTEST__XXX

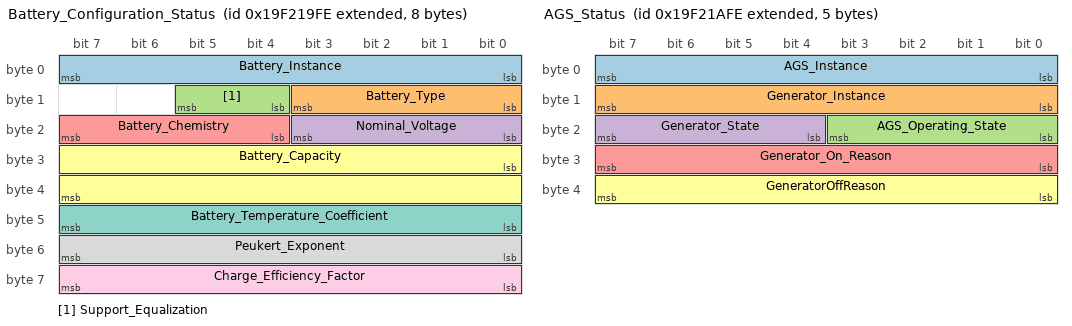
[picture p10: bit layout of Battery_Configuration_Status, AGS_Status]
BO_ 2582780414 Battery_Configuration_Status: 8 EXXOTEST__XXX
 SG_ Battery_Instance : 0|8@1+ (1,0) [0|252] ""  EXXOTEST__XXX
 SG_ Battery_Type : 8|4@1+ (1,0) [0|1] ""  EXXOTEST__XXX
 SG_ Support_Equalization : 12|2@1+ (1,0) [0|1] ""  EXXOTEST__XXX
 SG_ Nominal_Voltage : 16|4@1+ (1,0) [0|1] ""  EXXOTEST__XXX
 SG_ Battery_Chemistry : 20|4@1+ (1,0) [0|1] ""  EXXOTEST__XXX
 SG_ Battery_Capacity : 24|16@1+ (3600,0) [0|235915200] "C"  EXXOTEST__XXX
 SG_ Battery_Temperature_Coefficient : 40|8@1- (1,0) [-124|124] "%"  EXXOTEST__XXX
 SG_ Peukert_Exponent : 48|8@1+ (0.002,0) [1|1.5] ""  EXXOTEST__XXX
 SG_ Charge_Efficiency_Factor : 56|8@1- (1,0) [-124|124] "%"  EXXOTEST__XXX

BO_ 2582780670 AGS_Status: 5 EXXOTEST__XXX
 SG_ AGS_Instance : 0|8@1+ (1,0) [0|252] ""  EXXOTEST__XXX
 SG_ Generator_Instance : 8|8@1+ (1,0) [0|252] ""  EXXOTEST__XXX
 SG_ AGS_Operating_State : 16|4@1+ (1,0) [0|1] ""  EXXOTEST__XXX
 SG_ Generator_State : 20|4@1+ (1,0) [0|1] ""  EXXOTEST__XXX
 SG_ Generator_On_Reason : 24|8@1+ (1,0) [0|1] ""  EXXOTEST__XXX
 SG_ GeneratorOffReason : 32|8@1+ (1,0) [0|1] ""  EXXOTEST__XXX

BO_ 2650476286 AIS_Channel_Management: 31 EXXOTEST__XXX
 SG_ MessageID : 0|6@1+ (1,0) [0|1] ""  EXXOTEST__XXX
 SG_ Repeat_Indicator : 6|2@1+ (1,0) [0|1] ""  EXXOTEST__XXX
 SG_ StationID : 8|32@1+ (1,0) [0|4294967292] ""  EXXOTEST__XXX
 SG_ AIS_Transceiver_Information : 41|5@1+ (1,0) [0|1] ""  EXXOTEST__XXX
 SG_ Channel_A : 48|16@1+ (1,0) [0|65.532] ""  EXXOTEST__XXX
 SG_ Channel_B : 64|16@1+ (1,0) [0|65.532] ""  EXXOTEST__XXX
 SG_ Power : 83|1@1+ (1,0) [0|1] ""  EXXOTEST__XXX
 SG_ TxRx_Mode : 84|4@1+ (1,0) [0|1] ""  EXXOTEST__XXX
 SG_ North_East_Longitude_Corner_1 : 88|32@1- (1E-07,0) [-180|180] "deg"  EXXOTEST__XXX
 SG_ North_East_Latitude_Corner_1 : 120|32@1- (1E-07,0) [-90|90] "deg"  EXXOTEST__XXX
 SG_ South_West_Longitude_Corner_2 : 152|32@1- (1E-07,0) [-180|180] "deg"  EXXOTEST__XXX
 SG_ South_West_Latitude_Corner_2 : 184|32@1- (1E-07,0) [-90|90] "deg"  EXXOTEST__XXX
 SG_ Addressed_or_Broadcast_Message_I : 217|1@1+ (1,0) [0|1] ""  EXXOTEST__XXX
 SG_ Channel_A_Bandwidth : 218|1@1+ (1,0) [0|1] ""  EXXOTEST__XXX
 SG_ Channel_B_Bandwidth : 219|1@1+ (1,0) [0|1] ""  EXXOTEST__XXX
 SG_ Transitional_Zone_Site : 221|3@1+ (1,0) [0|1] ""  EXXOTEST__XXX

BO_ 2650476542 AIS_Class_B_Group_Assignment: 32 EXXOTEST__XXX
 SG_ MessageID : 0|12@1+ (1,0) [0|1] ""  EXXOTEST__XXX
 SG_ Repeat_Indicator : 12|4@1+ (1,0) [0|1] ""  EXXOTEST__XXX
 SG_ SourceID : 16|32@1+ (1,0) [0|4294967292] ""  EXXOTEST__XXX
 SG_ TxRx_Mode : 50|8@1+ (1,0) [0|1] ""  EXXOTEST__XXX
 SG_ North_East_Longitude_Corner_1 : 60|32@1- (1E-07,0) [-180|180] "deg"  EXXOTEST__XXX
 SG_ North_East_Latitude_Corner_1 : 92|32@1- (1E-07,0) [-90|90] "deg"  EXXOTEST__XXX
 SG_ South_West_Longitude_Corner_2 : 124|32@1- (1E-07,0) [-180|180] "deg"  EXXOTEST__XXX
 SG_ South_West_Latitude_Corner_2 : 156|32@1- (1E-07,0) [-90|90] "deg"  EXXOTEST__XXX
 SG_ Station_Type : 188|8@1+ (1,0) [0|1] ""  EXXOTEST__XXX
 SG_ Ship_and_Cargo_Filter : 200|8@1+ (1,0) [0|1] ""  EXXOTEST__XXX
 SG_ Reporting_Interval : 232|8@1+ (1,0) [0|1] ""  EXXOTEST__XXX
 SG_ Quiet_Time : 240|8@1+ (1,0) [0|1] ""  EXXOTEST__XXX

BO_ 2583368190 AIS_Class_B_CS_Static_Data_Repor: 26 EXXOTEST__XXX
 SG_ MessageID : 0|12@1+ (1,0) [0|1] ""  EXXOTEST__XXX
 SG_ Repeat_Indicator : 12|4@1+ (1,0) [0|1] ""  EXXOTEST__XXX
 SG_ UserID : 16|32@1+ (1,0) [0|4294967292] ""  EXXOTEST__XXX
 SG_ Name : 48|160@1+ (1,0) [0|255] "ASCII"  EXXOTEST__XXX

BO_ 2583368446 AIS_Class_B_CS_Static_Data__0000: 35 EXXOTEST__XXX
 SG_ MessageID : 0|12@1+ (1,0) [0|1] ""  EXXOTEST__XXX
 SG_ Repeat_Indicator : 12|4@1+ (1,0) [0|1] ""  EXXOTEST__XXX
 SG_ UserID : 16|32@1+ (1,0) [0|4294967292] ""  EXXOTEST__XXX
 SG_ Type_Of_Ship_And_Cargo : 48|16@1+ (1,0) [0|1] ""  EXXOTEST__XXX
 SG_ VendorID : 64|56@1+ (1,0) [0|255] "ASCII"  EXXOTEST__XXX
 SG_ Call_Sign : 120|56@1+ (1,0) [0|255] "ASCII"  EXXOTEST__XXX
 SG_ Ship_Length : 176|16@1+ (0.1,0) [0|6553.2] "m"  EXXOTEST__XXX
 SG_ Ship_Beam : 192|16@1+ (0.1,0) [0|6553.2] "m"  EXXOTEST__XXX
 SG_ Reference_Point_Position_from_St : 208|16@1+ (0.1,0) [0|6553.2] "m"  EXXOTEST__XXX
 SG_ Reference_Point_Position_Aft_of_ : 224|16@1+ (0.1,0) [0|6553.2] "m"  EXXOTEST__XXX
 SG_ Mother_Ship_MMSI : 240|32@1+ (1,0) [0|4294967292] ""  EXXOTEST__XXX

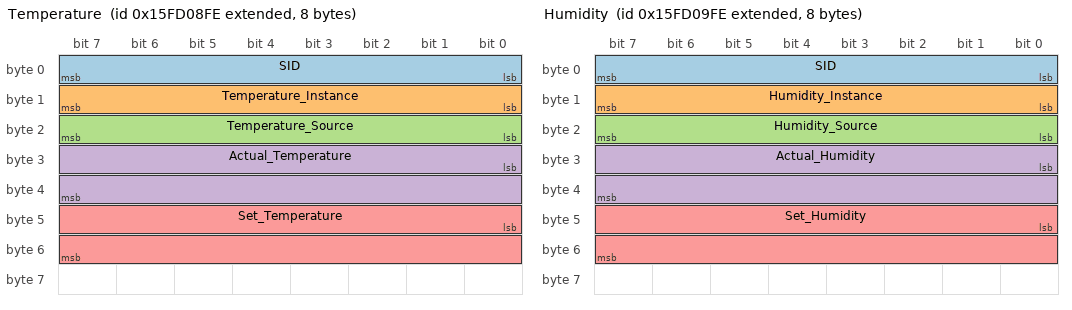
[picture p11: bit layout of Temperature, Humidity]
BO_ 2516388094 Temperature: 8 EXXOTEST__XXX
 SG_ SID : 0|8@1+ (1,0) [0|252] ""  EXXOTEST__XXX
 SG_ Temperature_Instance : 8|8@1+ (1,0) [0|1] ""  EXXOTEST__XXX
 SG_ Temperature_Source : 16|8@1+ (1,0) [0|1] ""  EXXOTEST__XXX
 SG_ Actual_Temperature : 24|16@1+ (0.01,0) [0|655.32] "degK"  EXXOTEST__XXX
 SG_ Set_Temperature : 40|16@1+ (0.01,0) [0|655.32] "degK"  EXXOTEST__XXX

BO_ 2516388350 Humidity: 8 EXXOTEST__XXX
 SG_ SID : 0|8@1+ (1,0) [0|252] ""  EXXOTEST__XXX
 SG_ Humidity_Instance : 8|8@1+ (1,0) [0|1] ""  EXXOTEST__XXX
 SG_ Humidity_Source : 16|8@1+ (1,0) [0|1] ""  EXXOTEST__XXX
 SG_ Actual_Humidity : 24|16@1- (0.004,0) [-131.072|131.056] "%"  EXXOTEST__XXX
 SG_ Set_Humidity : 40|16@1+ (0.004,0) [-131.072|131.056] "%"  EXXOTEST__XXX

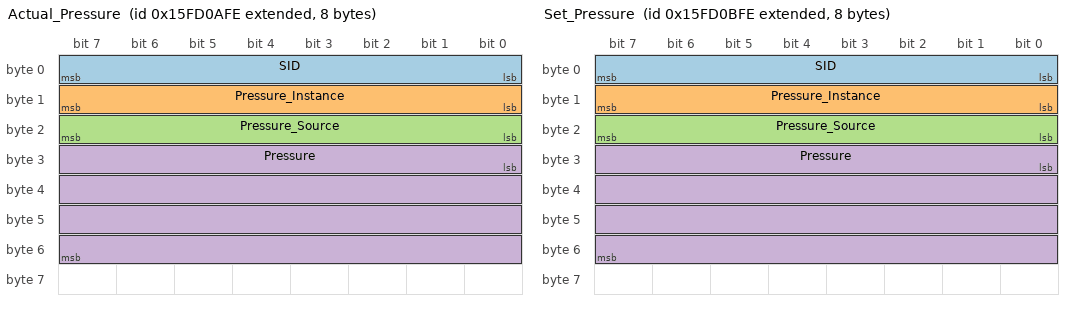
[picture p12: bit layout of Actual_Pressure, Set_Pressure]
BO_ 2516388606 Actual_Pressure: 8 EXXOTEST__XXX
 SG_ SID : 0|8@1+ (1,0) [0|252] ""  EXXOTEST__XXX
 SG_ Pressure_Instance : 8|8@1+ (1,0) [0|1] ""  EXXOTEST__XXX
 SG_ Pressure_Source : 16|8@1+ (1,0) [0|1] ""  EXXOTEST__XXX
 SG_ Pressure : 24|32@1- (0.1,0) [-210000000|210000000] "Pa"  EXXOTEST__XXX

BO_ 2516388862 Set_Pressure: 8 EXXOTEST__XXX
 SG_ SID : 0|8@1+ (1,0) [0|252] ""  EXXOTEST__XXX
 SG_ Pressure_Instance : 8|8@1+ (1,0) [0|1] ""  EXXOTEST__XXX
 SG_ Pressure_Source : 16|8@1+ (1,0) [0|1] ""  EXXOTEST__XXX
 SG_ Pressure : 24|32@1- (0.1,0) [-210000000|210000000] "Pa"  EXXOTEST__XXX

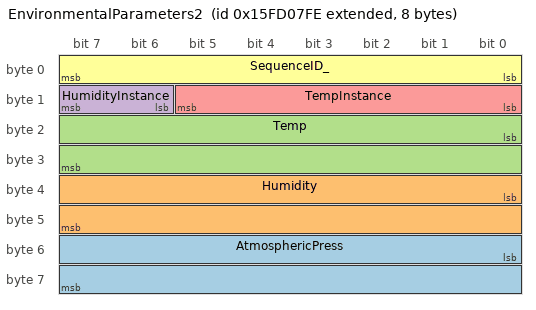
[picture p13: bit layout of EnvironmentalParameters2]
BO_ 2516387838 EnvironmentalParameters2: 8 EXXOTEST__XXX
 SG_ AtmosphericPress : 48|16@1+ (100,0) [0|6553200] "Pa"  EXXOTEST__XXX
 SG_ Humidity : 32|16@1- (0.004,0) [-131.072|131.056] "%"  EXXOTEST__XXX
 SG_ Temp : 16|16@1+ (0.01,0) [0|655.32] "°K"  EXXOTEST__XXX
 SG_ HumidityInstance : 14|2@1+ (1,0) [0|3] ""  EXXOTEST__XXX
 SG_ TempInstance : 8|6@1+ (1,0) [0|63] ""  EXXOTEST__XXX
 SG_ SequenceID_ : 0|8@1+ (1,0) [0|252] ""  EXXOTEST__XXX

BO_ 2582648062 ProductInformation: 132 EXXOTEST__XXX
 SG_ ManufacturersModelSerialCode : 800|256@1+ (1,0) [0|255] "ASCII"  EXXOTEST__XXX
 SG_ ManufacturersModelVersion : 544|256@1+ (1,0) [0|255] "ASCII"  EXXOTEST__XXX
 SG_ ManufacturersSoftwareVersionCode : 288|256@1+ (1,0) [0|255] "ASCII"  EXXOTEST__XXX
 SG_ ManufacturersModelID : 32|256@1+ (1,0) [0|255] "ASCII"  EXXOTEST__XXX
 SG_ NMEAManufacturersProductCode : 16|16@1+ (1,0) [0|65532] ""  EXXOTEST__XXX
 SG_ NMEA2000DatabaseVersion : 0|16@1+ (1,0) [0|65532] ""  EXXOTEST__XXX

BO_ 2582648574 ConfigInformation: 24 EXXOTEST__XXX
 SG_ ManufacturerInformationField3 : 128|64@1+ (1,0) [0|255] "ASCII"  EXXOTEST__XXX
 SG_ InstallationDescriptionField2 : 64|64@1+ (1,0) [0|255] "ASCII"  EXXOTEST__XXX
 SG_ InstallationDescriptionField1 : 0|64@1+ (1,0) [0|255] "ASCII"  EXXOTEST__XXX

BO_ 2582576894 PGNLstTransmitPGNsGroupFunction: 40 EXXOTEST__XXX
 SG_ VrblNmbrOfFldsFldNmber2Repeated2 m1 : 32|24@1+ (1,0) [0|16777215] ""  EXXOTEST__XXX
 SG_ FirstPGNSupported2 m1 : 8|24@1+ (1,0) [0|16777215] ""  EXXOTEST__XXX
 SG_ VrblNmbrOfFldsFldNmber2Repeated m0 : 32|24@1+ (1,0) [0|16777215] ""  EXXOTEST__XXX
 SG_ FirstPGNSupported m0 : 8|24@1+ (1,0) [0|16777215] ""  EXXOTEST__XXX
 SG_ GrpFnctnTrnsmtAndReceivePGNList M : 0|8@1+ (1,0) [0|252] ""  EXXOTEST__XXX
 SG_ PGNSupported3 m0 : 56|24@1+ (1,0) [0|16777215] ""  EXXOTEST__XXX
 SG_ PGNSupported4 m0 : 80|24@1+ (1,0) [0|16777215] ""  EXXOTEST__XXX
 SG_ PGNSupported5 m0 : 104|24@1+ (1,0) [0|16777215] ""  EXXOTEST__XXX
 SG_ PGNSupported3_2 m1 : 56|24@1+ (1,0) [0|16777215] ""  EXXOTEST__XXX
 SG_ PGNSupported4_2 m1 : 80|24@1+ (1,0) [0|16777215] ""  EXXOTEST__XXX
 SG_ PGNSupported5_2 m1 : 104|24@1+ (1,0) [0|16777215] ""  EXXOTEST__XXX

CM_ BO_ 2565799678 "Address_Claimed";
CM_ SG_ 2565799678 IndustryGroup "0_=_Global_";
CM_ SG_ 2565799678 ManufacturerCode "Assigned_by_NMEA_2000_Committee";
CM_ BO_ 2632711934 "Transport_Protocol_-_Data_Transfer";
CM_ BO_ 2632777470 "Transport_Protocol_-_Connection_Management";
CM_ SG_ 2632777470 TotalNumberOfPacketsEoMA "Total_number_of_packets_for_BAM_message.Total_number_of_packets_received_for_RTS/CTS_message.Total_number_of_packets_for_RTS/CTS_message.";
CM_ SG_ 2632777470 TotalMessageSizeEoMA "Total_message_size_(in_bytes)_for_BAM_message.Total_message_size_(in_bytes)_for_RTS/CTS_message.Total_message_size_(in_bytes)_for_RTS/CTS_message.";
CM_ SG_ 2632777470 TotalMessageSizeBAM "Total_message_size_(in_bytes)_for_BAM_message.Total_message_size_(in_bytes)_for_RTS/CTS_message.Total_message_size_(in_bytes)_for_RTS/CTS_message.";
CM_ SG_ 2632777470 TotalNumberOfPacketsBAM "Total_number_of_packets_for_BAM_message.Total_number_of_packets_received_for_RTS/CTS_message.Total_number_of_packets_for_RTS/CTS_message.";
CM_ SG_ 2632777470 ConnectionAbortReason "Reason_for_connection_abort_message.";
CM_ SG_ 2632777470 NextPacketNumberToBeSent "Next_Packet_Number_to_be_sent_(TP.CM_CTS)";
CM_ SG_ 2632777470 NumberOfPacketsThatCanBeSent "Number_of_Packets_that_can_be_sent_(TP.CM_CTS)";
CM_ SG_ 2632777470 MaximumNumberOfPackets "Maximum_number_of_packets_for_RTS/CTS_message.";
CM_ SG_ 2632777470 TotalNumberOfPackets "Total_number_of_packets_for_BAM_message.Total_number_of_packets_received_for_RTS/CTS_message.Total_number_of_packets_for_RTS/CTS_message.";
CM_ SG_ 2632777470 TotalMessageSize "Total_message_size_(in_bytes)_for_BAM_message.Total_message_size_(in_bytes)_for_RTS/CTS_message.Total_message_size_(in_bytes)_for_RTS/CTS_message.";
CM_ BO_ 2565537534 "Request";
CM_ SG_ 2565537534 ParameterGroupNumber "PGN_which_is_requested_by_Request2_message";
CM_ BO_ 2315059966 "Direction_and_speed_of_WindTrue_wind_can_be_referenced_to_vessel_to_groundApparent_Wind_is_what_is_felt_standing_on_themovingship,Ie,wind_measured_by_typical_mast_head_instruments_boat_referenced_true_wind_is_given_by_vector_sum_of_Apparent_wind_a";
CM_ SG_ 2315059966 WindReference "0x00_=_True_(referenced_to_North)_0x01_=_Magnetic_0x02_=_Apparent_0x03_=_True_(boat_referenced)_0x04_=_Reserved_0x05_=_Reserved_0x06_=_Error_0x07_=_Null";
CM_ SG_ 2315059966 SequenceID_ "An_upward_counting_number_used_to_tie_related_information_together_between_different_PGNs.For_example,SID_would_be_used_to_tie_together_COG,SOG_and_RAIM_values_to_a_given_Pos.255=no_valid_Pos_fix_to_tie_it_to.Range_0_to_250_for_valid_Pos_fixes.";
CM_ BO_ 2381646846 "Water_depth_relative_to_transducer_and_offset_of_measuring_transducerPositive_offset_numbers_provide_distance_from_transducer_to_waterlineNegative_offset_numbers_provide_distance_from_transducer_to_part_of_keel_of_interest";
CM_ SG_ 2381646846 Offset "Positive_values_represent_distance_from_transducer_to_water_line_and_negative_values_represent_distance_from_the_transducer_to_the_keel.";
CM_ SG_ 2381646846 WaterDepthTransducer "Depth_relative_to_the_transducer_location.__Range_of_value_specified_in_'Maximum_Range'_field.";
CM_ SG_ 2381646846 SID "An_upward_counting_number_used_to_tie_related_information_together_between_different_PGNs.For_example,SID_would_be_used_to_tie_together_COG,SOG_and_RAIM_values_to_a_given_Pos.255=no_valid_Pos_fix_to_tie_it_to.Range_0_to_250_for_valid_Pos_fixes.";
CM_ BO_ 2315129598 "This_PGN_provides_a_single_Trans_that_accurately_describes_speed_of_a_vessel_by_component_vectors_This_information_is_relevant_for_large_vessels_and_would_typically_be_provided_by_a_product_that_interfaces_to_sensors_such_as_dual_axis_logsProducts_th";
CM_ SG_ 2315129598 SternSpeedGroundreferenced "Positive_values_represent_ahead_or_starboard_transverse_speed_and_negative_values_represent_astern_or_port_transverse_speed.";
CM_ SG_ 2315129598 SternSpeedWaterreferenced "Positive_values_represent_ahead_or_starboard_transverse_speed_and_negative_values_represent_astern_or_port_transverse_speed.";
CM_ SG_ 2315129598 TransverseSpeedGroundreferenced "Positive_values_represent_ahead_or_starboard_transverse_speed_and_negative_values_represent_astern_or_port_transverse_speed.";
CM_ SG_ 2315129598 LngtudinalSpeedGroundreferenced "Positive_values_represent_ahead_or_starboard_transverse_speed_and_negative_values_represent_astern_or_port_transverse_speed.";
CM_ SG_ 2315129598 TransverseSpeedWaterreferenced "Positive_values_represent_ahead_or_starboard_transverse_speed_and_negative_values_represent_astern_or_port_transverse_speed.";
CM_ SG_ 2315129598 LngitudinalSpeedWaterreferenced "Positive_values_represent_ahead_or_starboard_transverse_speed_and_negative_values_represent_astern_or_port_transverse_speed.";
CM_ BO_ 2314277630 "Heading_sensor_value_with_a_flag_for_True_MagneticIf_sensor_value_is_Magnetic,deviation_field_can_be_used_to_produce_a_Magnetic_heading,and_variation_field_can_be_used_to_correct_Magnetic_heading_to_produce_a_True_heading_To_obtain_Magnetic_Heading_f";
CM_ SG_ 2314277630 HeadingSensorReference "0_=_True,__1_=_Magnetic,_2_=_Error,_3_=_Null";
CM_ SG_ 2314277630 Variation "Positive_values_are_Easterly_and_negative_values_are_Westerly.";
CM_ SG_ 2314277630 Deviation "Positive_values_are_Easterly_and_negative_values_are_Westerly.";
CM_ SG_ 2314277630 HeadingSensorReading "Primary_output_of_heading_as_indicated_by_the_heading_sensor.";
CM_ SG_ 2314277630 SID "An_upward_counting_number_used_to_tie_related_information_together_between_different_PGNs.For_example,SID_would_be_used_to_tie_together_COG,SOG_and_RAIM_values_to_a_given_Pos.255=no_valid_Pos_fix_to_tie_it_to.Range_0_to_250_for_valid_Pos_fixes.";
CM_ BO_ 2583172606 "Transformation_parameters_for_converting_from_WGS-84_to_other_Datums";
CM_ BO_ 2515667198 "Trip_parameters_relative_to_Vessel";
CM_ BO_ 2515667454 "Engine_related_trip_information";
CM_ SG_ 2515667454 EngInstance "For_Engs:_0_=_Instance_";
CM_ BO_ 2314339838 "Used_to_provide_operational_state_and_internal_operating_parameters_of_a_specific_Trans,indicated_by_Trans_instance_fieldThis_Msg_would_normally_be_broadcasted_periodically_to_provide_information_for_instrumentation_Ctrl_functions";
CM_ SG_ 2314339838 TransDiscreteStatus "xxxx_xxx1_=_Check_Tranmission,_xxxx_xx1x_=_Over_Temp,_xxxx_x1xx_=_Low_Oil_Press,_xxxx_1xxx_=_Low_Oil_Level,_xxx1_xxxx_=_Sail_Drive,_xx1x_xxxx_=_reserved,_x1xx_xxxx_=_reserved,_1xxx_xxxx_=_reserved,_where_x_=_don't_care";
CM_ SG_ 2314339838 TransGear "0_=_Forward._1_=_Neutral,_2_=_Reverse,_3_=_[Unavailable,_Unknown]";
CM_ SG_ 2314339838 TransInstance "For_Engs:_0_=_Instance_";
CM_ BO_ 2314602750 "Message_for_reporting_status_and_target_data_from_tracking_radar_external_devices__The_reporting_interval_will_vary_by_the_values_for_target_status_and_quantity_of_track_data_files";
CM_ SG_ 2314602750 Course "Degrees_clockwise_relative_to_True_North.";
CM_ SG_ 2314602750 Bearing "Degrees_clockwise_relative_to_True_North.";
CM_ SG_ 2314602750 BearingReference "0_=_True,__1_=_Magnetic,_2_=_Error,_3_=_Releative";
CM_ SG_ 2314602750 TrackStatus "xx00_=_Cancelled_Not_Available,_xx01_=_Initial_Acquisition_Target,_xx10_=_Tracking_Target,_xx11_=_Lost_Target,_x0xx_=_Reported_Target_No,_x1xx_=_Reported_Target_Yes,_0xxx_=_Acquision_Manual,_1xxx_=_Acquision_Auto,_where_x_=_don";
CM_ SG_ 2314602750 TargetID "Number_of_route,_waypoint,_event,_mark,_etc.";
CM_ SG_ 2314602750 SequenceID_ "An_upward_counting_number_used_to_tie_related_information_together_between_different_PGNs.For_example,SID_would_be_used_to_tie_together_COG,SOG_and_RAIM_values_to_a_given_Pos.255=no_valid_Pos_fix_to_tie_it_to.Range_0_to_250_for_valid_Pos_fixes.";
CM_ SG_ 2314602750 Name "Name_of_place,_route,_waypoint,_destination,_vessel,_vehicle,_etc.";
CM_ SG_ 2314602750 UTCOfFix "24_hour_clock,_0_=__midnight,__time_is_in_UTC";
CM_ SG_ 2314602750 TCPA "Time_interval_in_milli-sec.__'-'__=_time_elapsed_since_event,_'+'_=_time_to_go_before_event.";
CM_ BO_ 2650544894 "Complex_Rq_of_this_PGN_should_return_Waypoints_of_a_WP-List_WARNING:Route_Track_may_not_be_defined_by_Waypoint_Poss_only:Navigation_MethodGC/RLand_Radius_of_Turn_at_each_Waypoint_are_optional_additional_parameters_defining_Track_PGN_130066_field_";
CM_ SG_ 2650544894 WPName "Name_of_place,_route,_waypoint,_destination,_vessel,_vehicle,_etc.";
CM_ SG_ 2650544894 WPID "Number_of_route,_waypoint,_event,_mark,_etc.";
CM_ SG_ 2650544894 reserved "Number_of_route,_waypoint,_event,_mark,_etc.";
CM_ SG_ 2650544894 DatabaseID "Number_of_route,_waypoint,_event,_mark,_etc.";
CM_ SG_ 2650544894 NumberOfValidWPsInWPList "Number_of_route,_waypoint,_event,_mark,_etc.";
CM_ SG_ 2650544894 nItems "Number_of_route,_waypoint,_event,_mark,_etc.";
CM_ SG_ 2650544894 StartWPID "Number_of_route,_waypoint,_event,_mark,_etc.";
CM_ BO_ 2650544382 "Complex_Rq_of_this_PGN_should_return_supplementary_Comments_attached_to_Databases_in_navigation_Device_Databases_without_a_Comment_shall_not_be_included_in_this_PGN_reply_should_use_same_transfer_Protcl_as_Rq_ISO_Rq_for_this_PGN_shall_return_059";
CM_ SG_ 2650544382 DatabaseID "Number_of_route,_waypoint,_event,_mark,_etc.";
CM_ SG_ 2650544382 NumberOfDatabasesWithComments "Number_of_route,_waypoint,_event,_mark,_etc.";
CM_ SG_ 2650544382 nItems "Number_of_route,_waypoint,_event,_mark,_etc.";
CM_ SG_ 2650544382 StartDatabaseID "Number_of_route,_waypoint,_event,_mark,_etc.";
CM_ BO_ 2314276350 "Rudderder_Cmd_in_direction_angle_with_current_rudder_angle_readingDirectionder_field_is_for_non-follow-up_rudderders_and_Angleder_field_is_for_follow-up_rudderdersWhen_used_as_a_Cmd,Directionder_field_and_Angleder_field_shall_never_containder_values_at_";
CM_ SG_ 2314276350 Pos "Rudder_angle_where_positive_values_are_starboard_and_negative_values_are_port";
CM_ SG_ 2314276350 Angleder "Rudder_angle_where_positive_values_are_starboard_and_negative_values_are_port";
CM_ SG_ 2314276350 Directionder "MSB/LSB:__000_=_No_Order,_001_=_Move_to_starboard,_010_=_Move_to_port.";
CM_ SG_ 2314276350 RudderInstance "For_Engs:_0_=_Instance_";
CM_ BO_ 2650543614 "Complex_Rq_of_this_PGN_will_return_XTE_Limit_and/or_Navigation_Method_specific_to_individual_legs_of_a_Route_Database_ID_and_Route_ID_shall_be_specified_in_Rq/reply_parameters_apply_to_one_leg_after_Waypoint_identified_with_RPS_in_Forward_Directi";
CM_ SG_ 2650543614 NavMethodInLegAfterWP "0_=_Great_Circle_calculations,__1_=_Rhumb_Line_calculations,_2_=_Error,_3_=_Null";
CM_ SG_ 2650543614 XTELimitInLegAfterWP "A_commanded_distance_like_radius_order,_off-track_limit,_etc.";
CM_ SG_ 2650543614 RPS "Number_of_route,_waypoint,_event,_mark,_etc.";
CM_ SG_ 2650543614 RouteID "Number_of_route,_waypoint,_event,_mark,_etc.";
CM_ SG_ 2650543614 DatabaseID "Number_of_route,_waypoint,_event,_mark,_etc.";
CM_ SG_ 2650543614 NmbrOfWypntsWthASpcfcXTELmtNvMth "Number_of_route,_waypoint,_event,_mark,_etc.";
CM_ SG_ 2650543614 nItems "Number_of_route,_waypoint,_event,_mark,_etc.";
CM_ SG_ 2650543614 StartRPS "Number_of_route,_waypoint,_event,_mark,_etc.";
CM_ BO_ 2650542846 "Complex_Rq_for_this_PGN_should_return_attributes_of_a_Route_WP-List_WARNING:Route_Track_may_not_be_defined_by_Waypoint_Poss_only:Navigation_MethodGC/RLand_Radius_of_Turn_at_each_Waypoint_are_optional_additional_parameters_defining_Track_PGN_130066";
CM_ SG_ 2650542846 Route_WPListName "Name_of_place,_route,_waypoint,_destination,_vessel,_vehicle,_etc.";
CM_ SG_ 2650542846 RouteID "Number_of_route,_waypoint,_event,_mark,_etc.";
CM_ SG_ 2650542846 DatabaseID "Number_of_route,_waypoint,_event,_mark,_etc.";
CM_ BO_ 2650543870 "Complex_Rq_of_this_PGN_should_return_supplementary_Comments_attached_to_Waypoints_in_a_Route_a_WP-List_Waypoints_without_a_Commment_shall_not_be_included_in_this_PGN_If_Route_ID_is_set_to_65535NA,Comments_will_be_for_Waypoints_in_WP-List_Datab";
CM_ SG_ 2650543870 WPID_RPS "Number_of_route,_waypoint,_event,_mark,_etc.";
CM_ SG_ 2650543870 RouteID "Number_of_route,_waypoint,_event,_mark,_etc.";
CM_ SG_ 2650543870 DatabaseID "Number_of_route,_waypoint,_event,_mark,_etc.";
CM_ SG_ 2650543870 NumberOfWPsWithComments "Number_of_route,_waypoint,_event,_mark,_etc.";
CM_ SG_ 2650543870 nItems "Number_of_route,_waypoint,_event,_mark,_etc.";
CM_ SG_ 2650543870 StartID "Number_of_route,_waypoint,_event,_mark,_etc.";
CM_ BO_ 2583300606 "This_PGN_is_used_to_provide_the_output_from_a_GNSS_Receivers_Receiver_Autonomous_Integrity_Monitoring_RAIM_process__The_Integrity_field_value_is_based_upon_the_parameters_set_in_PGN_130059_GNS_RAIM_Settings";
CM_ SG_ 2583300606 SVIDOfMostLikelyFailedSat "0_=_value_not_used,_1-32_=_GPS,_33-64_=_SBAS,Satellite,Based_Augmentation_System(ie_WAAS)_65-96_=_GLONASS._For_GLONASS,satellites_are_identified_by_64+satellite_slot_number.slot_numbers_are_1_through_24_for_full_GLONASS_constellation_of_24_satellite";
CM_ SG_ 2583300606 IntegrityFlag "0_=_No_Integrity_checking,*_1_=_Safe,_2_=_Caution,_3_=_Unsafe_*_means_the_receiver_does_not_have_this_capability";
CM_ SG_ 2583300606 SequenceID_ "An_upward_counting_number_used_to_tie_related_information_together_between_different_PGNs.For_example,SID_would_be_used_to_tie_together_COG,SOG_and_RAIM_values_to_a_given_Pos.255=no_valid_Pos_fix_to_tie_it_to.Range_0_to_250_for_valid_Pos_fixes.";
CM_ BO_ 2583299838 "GNSS_pseudorange_measurement_noise_statistics_can_be_translated_in_the_position_domain_in_order_to_give_statistical_measures_of_the_quality_of_the_position_solution_Intended_for_use_with_a_Receiver_Autonomous_Integrity_Monitoring_RAIM_application";
CM_ SG_ 2583299838 STDOfAltError "Error_distances_expressed_in_meters.";
CM_ SG_ 2583299838 STDOfLonError "Error_distances_expressed_in_meters.";
CM_ SG_ 2583299838 STDOfLatError "Error_distances_expressed_in_meters.";
CM_ SG_ 2583299838 OrientationOfMajorAxis "Degrees_clockwise_relative_to_True_North.";
CM_ SG_ 2583299838 STDOfMinorAxis "Error_distances_expressed_in_meters.";
CM_ SG_ 2583299838 STDOfMajorAxis "Error_distances_expressed_in_meters.";
CM_ SG_ 2583299838 RMSOfPosUncertainty "Error_distances_expressed_in_meters.";
CM_ SG_ 2583299838 SID "An_upward_counting_number_used_to_tie_related_information_together_between_different_PGNs.For_example,SID_would_be_used_to_tie_together_COG,SOG_and_RAIM_values_to_a_given_Pos.255=no_valid_Pos_fix_to_tie_it_to.Range_0_to_250_for_valid_Pos_fixes.";
CM_ BO_ 2583301118 "This_parameter_group_is_used_to_support_Receiver_Autononmous_Integrity_Monitoring_RAIM__Pseudorange_measurement_error_statistics_can_be_translated_in_the_position_domain_in_order_to_give_statistical_measures_of_the_quality_of_the_position_solution";
CM_ SG_ 2583301118 OrientationOfErrorEllipse "Degrees_clockwise_relative_to_True_North.";
CM_ SG_ 2583301118 SequenceID_ "An_upward_counting_number_used_to_tie_related_information_together_between_different_PGNs.For_example,SID_would_be_used_to_tie_together_COG,SOG_and_RAIM_values_to_a_given_Pos.255=no_valid_Pos_fix_to_tie_it_to.Range_0_to_250_for_valid_Pos_fixes.";
CM_ BO_ 2381841918 "This_PGN_conveys_a_comprehensive_set_of_Global_Navigation_Satellite_System_GNSS_parameters,_including_position_information__Equipment_transmitting_this_PGN_would_typically_also_transmit_PGN_129025_Position__Rapid_Update";
CM_ SG_ 2381841918 AgeOfDGNSSReferenceStationN "Age_of_Differential_corrections";
CM_ SG_ 2381841918 ReferenceStationIDN "Reference_Station_ID.__Reference_Station_number_as_provided_by_the_Service_Provider.[Reference_document_required]";
CM_ SG_ 2381841918 ReferenceStationTypeN "Reference_Station_Type.__0x0=GP";
CM_ SG_ 2381841918 AgeOfDGNSSCorrections1_ "Age_of_Differential_corrections";
CM_ SG_ 2381841918 ReferenceStationID1_ "Reference_Station_ID.__Reference_Station_number_as_provided_by_the_Service_Provider.[Reference_document_required]";
CM_ SG_ 2381841918 ReferenceStationType1 "Reference_Station_Type.__0x0=GP";
CM_ SG_ 2381841918 NumberOfReferenceStations_ "Numeric_count,_event_counter,_sequence_counter";
CM_ SG_ 2381841918 GeoidalSeparation_ "The_difference_between_the_earth_ellipsoid_and_mean-sea-level_(geoid)_defined_by_the_reference_datum_used_in_the_position_solution,_'-'_=_mean-sea-level_below_ellipsoid.__Reference_datum_is_defined_in_this_packet.";
CM_ SG_ 2381841918 PDOP_ "Dilution_of_Precision(DOP)indicates_contribution_of_satellite_Config_geometry_to_Posing_error.A_lower_DOP_value_is_preferred_because_less_error_is_being_introduced.Reported_as_components:HDOP(Horizontal),VDOP(Vertical),TDOP(Time).Min_DOP_value_is_1.0(no_e";
CM_ SG_ 2381841918 HDOP_ "Dilution_of_Precision(DOP)indicates_contribution_of_satellite_Config_geometry_to_Posing_error.A_lower_DOP_value_is_preferred_because_less_error_is_being_introduced.Reported_as_components:HDOP(Horizontal),VDOP(Vertical),TDOP(Time).Min_DOP_value_is_1.0(no_e";
CM_ SG_ 2381841918 NumberOfSVs_ "Numeric_count,_event_counter,_sequence_counter";
CM_ SG_ 2381841918 Integrity "0_=_No_Integrity_checking,*_1_=_Safe,_2_=_Caution,_3_=_Unsafe_*_means_the_receiver_does_not_have_this_capability";
CM_ SG_ 2381841918 MethodGNSS "0_=_no_GPS,_1_=_GNSS_fix,_2_=_DGNSS_fix,_3_=_Precise_GNSS*,_4_=_RTK_Fixed_Integer,_5_=_RTK_Float,_6_=_Est(DR)mode,_7_=_Manual_Input,_8_=_Simulate_mode,_9-13_=_Reserved,_14_=_Error,_15_=_Null.*Precise_GNSS_means_no_deliberate_degradation(such_as";
CM_ SG_ 2381841918 TypeOfSystem_ "0x00_=_GPS_0x01_=_GLONASS_0x02_=_GPS+GLONASS_0x03_=_GPS+SBAS(WAAS)_0x04_=_GPS+SBAS+GLONASS_0x05_-_0x15_=_Reserved_for_future_combinations";
CM_ SG_ 2381841918 PosTime "24_hour_clock,_0_=__midnight,__time_is_in_UTC";
CM_ SG_ 2381841918 PosDate "Days_since_January_1,_1970,___Date_is_relative_to_UTC_Time.";
CM_ SG_ 2381841918 SID "An_upward_counting_number_used_to_tie_related_information_together_between_different_PGNs.For_example,SID_would_be_used_to_tie_together_COG,SOG_and_RAIM_values_to_a_given_Pos.255=no_valid_Pos_fix_to_tie_it_to.Range_0_to_250_for_valid_Pos_fixes.";
CM_ BO_ 2583301886 "GNSS_common_differential_correction_receiver_parameter_status";
CM_ SG_ 2583301886 DiffOperationMode "0__=_Manual,__1_=_Auto_Power,_2_=_Auto_Range,_3-13_=_Reserved,_14_=_Error,_15_=_No_Selection";
CM_ SG_ 2583301886 DiffSource "0__=_Auto_Select,_1_=_Loran_Communications_2_=_MSK_Beacon,_3_=_FM_Subcarrier,_4_=_AIS(Automatic_Identification_System),_5_=_Other_Ground-based_Radio,_6_=_SBAS(Satellite_Based_Augmentation_System,_7_=_Other_Satellite,_8-13_=_Re";
CM_ SG_ 2583301886 SerialInterfaceDetectionMode "This_is_the_mode_of_operation_for_the_correction_receiver.___0_=_Auto_bit_rate_set,_1_=_Manual_bit_rate_set,_2-5_=_Reserved_6_=_Error,_7_=_Null.";
CM_ SG_ 2583301886 SerialInterfaceBitRate "This_is_bit_rate_of_correction_receiver._0_=_25bps,_1_=_50bps,_2_=_100bps,_3_=_200bps,_4_=_300bps,_5_=_500bps,_6_=_1200bps,_7_=_2400bps,_8_=_4800bps,_9_=_9600bps_10_=_19200bps,_11_=_38400bps,_12_=_57600bps,_13-29_=_Reserved,_30_=_";
CM_ SG_ 2583301886 Frequency "This_is_the_input_frequency_of_the_correction_receiver.";
CM_ SG_ 2583301886 Channel "The_channel_number_of_the_correction_receiver.__If_the_receiver_only_has_one_beacon_input_channel,_this_value_shall_be_1_0_is_undefined.";
CM_ BO_ 2583302142 "GNSS_differential_correction_receiver_status_tagged_by_sequence_ID_Status_information_includes_frequency,_SNR,_and_use_as_a_correction_source";
CM_ SG_ 2583302142 SatelliteServiceIDNo "Satellite_Service_ID_number_as_provided_by_the_Service_Provider.[Reference_document_required]";
CM_ SG_ 2583302142 TimeSinceLastSatDiffSync "Age_of_Differential_corrections";
CM_ SG_ 2583302142 DiffSource "0__=_Auto_Select,_1_=_Loran_Communications_2_=_MSK_Beacon,_3_=_FM_Subcarrier,_4_=_AIS(Automatic_Identification_System),_5_=_Other_Ground-based_Radio,_6_=_SBAS(Satellite_Based_Augmentation_System,_7_=_Other_Satellite,_8-13_=_Re";
CM_ SG_ 2583302142 UsedAsCorrectionSource "MSB/LSB:__00_=_[No,_Off,_Disabled,_Reset,_'0'],_01_=_[Yes,_On,_Enabled,_Set,_'1'],_10_=_Error,_11=_[Unavailable,_Unknown]";
CM_ SG_ 2583302142 DiffSignalDetectionMode "This_is_the_mode_of_operation_for_the_correction_receiver.___0_=_Auto_bit_rate_set,_1_=_Manual_bit_rate_set,_2-5_=_Reserved_6_=_Error,_7_=_Null.";
CM_ SG_ 2583302142 DiffSignalBitRate "This_is_bit_rate_of_correction_receiver._0_=_25bps,_1_=_50bps,_2_=_100bps,_3_=_200bps,_4_=_300bps,_5_=_500bps,_6_=_1200bps,_7_=_2400bps,_8_=_4800bps,_9_=_9600bps_10_=_19200bps,_11_=_38400bps,_12_=_57600bps,_13-29_=_Reserved,_30_=_";
CM_ SG_ 2583302142 StationID "Reference_Station_ID.__Reference_Station_number_as_provided_by_the_Service_Provider.[Reference_document_required]";
CM_ SG_ 2583302142 StationType "Reference_Station_Type.__0x0=GP";
CM_ SG_ 2583302142 Frequency "This_is_the_input_frequency_of_the_correction_receiver.";
CM_ SG_ 2583302142 SignalStrength "This_is_the_signal_strength_expressed_in_dB_with_respect_to_1uV/m.";
CM_ SG_ 2583302142 Channel "The_channel_number_of_the_correction_receiver.__If_the_receiver_only_has_one_beacon_input_channel,_this_value_shall_be_1_0_is_undefined.";
CM_ SG_ 2583302142 SID "An_upward_counting_number_used_to_tie_related_information_together_between_different_PGNs.For_example,SID_would_be_used_to_tie_together_COG,SOG_and_RAIM_values_to_a_given_Pos.255=no_valid_Pos_fix_to_tie_it_to.Range_0_to_250_for_valid_Pos_fixes.";
CM_ BO_ 2583299070 "This_PGN_provides_a_single_Trans_containing_GNSS_status_and_dilution_of_precision_componentsDOPthat_indicate_contribution_of_satellite_geometry_to_overall_Posing_errorThere_are_three_DOP_parameters_reported,horizontalHDOP,VerticalVDOPand_timeTDOP";
CM_ SG_ 2583299070 TDOP "Dilution_of_Precision(DOP)indicates_contribution_of_satellite_Config_geometry_to_Posing_error.A_lower_DOP_value_is_preferred_because_less_error_is_being_introduced.Reported_as_components:HDOP(Horizontal),VDOP(Vertical),TDOP(Time).Min_DOP_value_is_1.0(no_e";
CM_ SG_ 2583299070 VDOP "Dilution_of_Precision(DOP)indicates_contribution_of_satellite_Config_geometry_to_Posing_error.A_lower_DOP_value_is_preferred_because_less_error_is_being_introduced.Reported_as_components:HDOP(Horizontal),VDOP(Vertical),TDOP(Time).Min_DOP_value_is_1.0(no_e";
CM_ SG_ 2583299070 HDOP_ "Dilution_of_Precision(DOP)indicates_contribution_of_satellite_Config_geometry_to_Posing_error.A_lower_DOP_value_is_preferred_because_less_error_is_being_introduced.Reported_as_components:HDOP(Horizontal),VDOP(Vertical),TDOP(Time).Min_DOP_value_is_1.0(no_e";
CM_ SG_ 2583299070 OpMode "0_=_1D,__1_=_2D,_2_=_3D,_3_=_Auto,_4-5_=_Reserved,_6_=_Error,_7_=_Null";
CM_ SG_ 2583299070 SetMode "0_=_1D,__1_=_2D,_2_=_3D,_3_=_Auto,_4-5_=_Reserved,_6_=_Error,_7_=_Null";
CM_ SG_ 2583299070 SID "An_upward_counting_number_used_to_tie_related_information_together_between_different_PGNs.For_example,SID_would_be_used_to_tie_together_COG,SOG_and_RAIM_values_to_a_given_Pos.255=no_valid_Pos_fix_to_tie_it_to.Range_0_to_250_for_valid_Pos_fixes.";
CM_ BO_ 2583298814 "GNSS_common_satellite_receiver_parameter_status";
CM_ SG_ 2583298814 UseAntennaAltitudeFor2DMode "MSB/LSB:__00_=_[No,_Off,_Disabled,_Reset,_'0'],_01_=_[Yes,_On,_Enabled,_Set,_'1'],_10_=_Error,_11=_[Unavailable,_Unknown]";
CM_ SG_ 2583298814 MaxCorrectionAge "Age_of_Differential_corrections";
CM_ SG_ 2583298814 Pos_VelocityFilter "MSB/LSB:__00_=_[No,_Off,_Disabled,_Reset,_'0'],_01_=_[Yes,_On,_Enabled,_Set,_'1'],_10_=_Error,_11=_[Unavailable,_Unknown]";
CM_ SG_ 2583298814 DGNSSMode "0_=_Off,_1_=_Auto,_2_=_RTCM_SC104_Pseudorange_Corrections,_3_=_RTCA_SC159_Network_Corrections,_4_=_RTK_Differential_Corrections,_5_=_Reserved,_6_=_Erro";
CM_ SG_ 2583298814 GNSSMode "0_=_1D,__1_=_2D,_2_=_3D,_3_=_Auto,_4-5_=_Reserved,_6_=_Error,_7_=_Null";
CM_ SG_ 2583298814 PDOPSwitch "Dilution_of_Precision(DOP)indicates_contribution_of_satellite_Config_geometry_to_Posing_error.A_lower_DOP_value_is_preferred_because_less_error_is_being_introduced.Reported_as_components:HDOP(Horizontal),VDOP(Vertical),TDOP(Time).Min_DOP_value_is_1.0(no_e";
CM_ SG_ 2583298814 PDOPMask "Dilution_of_Precision(DOP)indicates_contribution_of_satellite_Config_geometry_to_Posing_error.A_lower_DOP_value_is_preferred_because_less_error_is_being_introduced.Reported_as_components:HDOP(Horizontal),VDOP(Vertical),TDOP(Time).Min_DOP_value_is_1.0(no_e";
CM_ SG_ 2583298814 SVElevationMask "Angle_above_or_below_the_horizon._-90°_to_+90°_negative_below_the_horizon";
CM_ BO_ 2583303422 "This_PGN_provides_a_single_Trans_that_contains_relevant_almanac_data_for_Glonass_productsalmanac_contains_satellite_vehicle_coursebital_parametersThis_information_is_not_considered_precise_and_is_only_valid_for_several_months_at_a_timeGlonass_products_";
CM_ SG_ 2583303422 tnA2 "Course_value_of_the_time_scale_shift,_reference_GLONASS_ICD_Section_4.5_Table_4.3_(fill_unused_bits_with_zeros).";
CM_ SG_ 2583303422 tcA "System_time_scale_correction,_reference_GLONASS_ICD_Section_4.5_Table_4.3_(fill_unused_bits_with_zeros).";
CM_ SG_ 2583303422 inA "Correction_to_the_average_value_of_the_inclination_angle,_reference_GLONASS_ICD_Section_4.5_Table_4.3_(fill_unused_bits_with_zeros).";
CM_ SG_ 2583303422 nA3 "Greenwich_longitude_of_the_ascension_node,_reference_GLONASS_ICD_Section_4.5_Table_4.3_(fill_unused_bits_with_zeros).";
CM_ SG_ 2583303422 tnA "Correction_to_the_average_value_of_the_draconitic_circling_time,_reference_GLONASS_ICD_Section_4.5_Table_4.3_(fill_unused_bits_with_zeros).";
CM_ SG_ 2583303422 TnA "Correction_to_the_average_value_of_the_draconitic_circling_time,_reference_GLONASS_ICD_Section_4.5_Table_4.3_(fill_unused_bits_with_zeros).";
CM_ SG_ 2583303422 nA2 "Argument_of_Perigee,_reference_GLONASS_ICD_Section_4.5_Table_4.3_(fill_unused_bits_with_zeros).";
CM_ SG_ 2583303422 DOT "Rate_of_change_of_the_draconitic_circling_time,_reference_GLONASS_ICD_Section_4.5_Table_4.3_(fill_unused_bits_with_zeros).";
CM_ SG_ 2583303422 nA "Calendar_day_count_within_the_four_year_period_beginning_with_the_previous_leap_year";
CM_ SG_ 2583303422 HnA "Carrier_frequency_number_respectively,_reference_GLONASS_ICD.";
CM_ SG_ 2583303422 CnA "Generalized_health_of_the_Satellite,_reference_GLONASS_ICD.";
CM_ SG_ 2583303422 NA "Calendar_day_count_within_the_four_year_period_beginning_with_the_previous_leap_year";
CM_ SG_ 2583303422 PRN "0_=_value_not_used,_1-32_=_GPS,_33-64_=_SBAS,Satellite,Based_Augmentation_System(ie_WAAS)_65-96_=_GLONASS._For_GLONASS,satellites_are_identified_by_64+satellite_slot_number.slot_numbers_are_1_through_24_for_full_GLONASS_constellation_of_24_satellite";
CM_ BO_ 2582778366 "Fluid_Level_contains_an_instance_number,_type_of_fluid,_level_of_fluid,_and_tank_capacity__For_example_the_fluid_instance_may_be_the_level_of_fuel_in_a_tank_or_the_level_of_water_in_the_bilge__Used_primarily_by_display_or_instrumentation_devices";
CM_ SG_ 2582778366 FluidType "0x00_=_Fuel,_0x01_=_Fresh_Water,_0x02_=_Waste_Water,_0x03_=_Live_Well,_0x04_=_Oil,_0x05_=_Black_Water_(Sewage)_0x06_=_Reserved,_thru_0x0D_=_Reserved,_0x0E_=_Error,_0x0F_=_Data_not_available";
CM_ SG_ 2582778366 FluidInstance "0x0_to_0xF_=_Instance_number_0_to_15";
CM_ BO_ 2516387582 "Local_atmospheric_environmental_conditions";
CM_ SG_ 2516387582 SequenceID_ "An_upward_counting_number_used_to_tie_related_information_together_between_different_PGNs.For_example,SID_would_be_used_to_tie_together_COG,SOG_and_RAIM_values_to_a_given_Pos.255=no_valid_Pos_fix_to_tie_it_to.Range_0_to_250_for_valid_Pos_fixes.";
CM_ BO_ 2515667710 "Provides_identification_information_and_rated_engine_speed_for_the_engine_indicated_by_the_engine_instance_field_Used_primarily_by_display_devices";
CM_ SG_ 2515667710 SoftwareID "Name_of_place,_route,_waypoint,_destination,_vessel,_vehicle,_etc.";
CM_ SG_ 2515667710 VIN "Name_of_place,_route,_waypoint,_destination,_vessel,_vehicle,_etc.";
CM_ SG_ 2515667710 EngInstance "For_Engs:_0_=_Instance_";
CM_ BO_ 2314338558 "Provides_data_with_a_high_update_rate_for_a_specific_engine_in_a_single_frame_message__The_first_field_provides_information_as_to_which_engine__This_PGN_if__used_with_PGN_127489_will_provide_most_Engine_data";
CM_ SG_ 2314338558 EngInstance "For_Engs:_0_=_Instance_";
CM_ BO_ 2314338814 "Used_to_provide_real-time_operational_data_and_status_relevant_to_a_specific_engine,__indicated_by_the_engine_instance_field__This_message_would_normally_be_broadcasted_periodically_to_provide_information_for_instrumentation_or_control_functions";
CM_ SG_ 2314338814 EngDiscreteStatus2 "xxxx_xxxx_xxxx_xxx1_=_Warning_Level_1,_xxxx_xxxx_xxxx_xx1x_=_Warning_Level_2,_xxxx_xxxx_xxxx_x1xx_=_Power_Reduction,_xxxx_xxxx_xxxx_1xxx_=_Maintenance_Needed,_xxxx_xxxx_xxx1_xxxx_=_Eng_Comm_Error,_xxxx_xxxx_xx1x_xxxx_=_Sub_Second_Throttle,_xxxx_xxxx";
CM_ SG_ 2314338814 EngDiscreteStatus1 "xxxx_xxxx__xxxx_xxx1_=_Check_Eng,_xxxx_xxxx_xxxx_xx1x_=_Over_Temp,_xxxx_xxxx_xxxx_x1xx_=_Low_Oil_Press,_xxxx_xxxx_xxxx_1xxx_=_Low_Oil_Level,_xxxx_xxxx_xxx1_xxxx_=_Low_Fuel_Press,_xxxx_xxxx_xx1x_xxxx_=_Low_System_Voltage,_xxxx_xxxx_x1xx_xxxx_=_";
CM_ SG_ 2314338814 EngInstance "For_Engs:_0_=_Instance_";
CM_ BO_ 2582975486 "This_PGN_provides_cumulative_voyage_distance_traveled_since_last_resetdistance_is_tagged_with_time_and_date_of_distance_measurementdistances_through_water_are_accumulated_and_values_stored_during_power_down_and_resume_counting_after_power_up_-Tota";
CM_ SG_ 2582975486 MeasurementTime "24_hour_clock,_0_=__midnight,__time_is_in_UTC";
CM_ SG_ 2582975486 MeasurementDate "Days_since_January_1,_1970,___Date_is_relative_to_UTC_Time.";
CM_ BO_ 2448953086 "This_parameter_group_provides_data_associated_with_ITU-R_M1371_Msgs_1,2,and_3_Pos_Reports,autonomous,assigned,and_Resp_to_interrogation,respectivelyAn_AIS_device_may_generate_this_parameter_group_either_upon_receiving_a_VHF_data_link_Msg_1,2_3,or_upon_r";
CM_ SG_ 2448953086 NavigationalStatus "0_=_under_way_using_Eng,_1_=_at_anchor,_2_=_not_under_Cmd,_3_=_restricted_manoeuvrability,_4_=_constrained_by_her_draught,_5_=_moored,_6_=_aground,_7_=_engaged_in_fishing,_8_=_under_way_sailing,_9_=_reserved_for_future_amendment_of_navigational_s";
CM_ SG_ 2448953086 RateOfTurn "+_=_Bow_turning_to_starboard,_1_deg/min_=_.00029_rad/sec";
CM_ SG_ 2448953086 TrueHeading "Degrees_clockwise_relative_to_True_North.";
CM_ SG_ 2448953086 AISTransceiverInformation "0_=_Channel_A_VDL_reception,_1_=_Channel_B_VDL_reception,_2_=_Channel_A_VDL_transmission,_3_=_Channel_B_VDL_transmission,_4_=_Own_information_not_broadcast,_5-31_=_Reserved.";
CM_ SG_ 2448953086 CommunicationState "The_Communication_State_contains_information_used_by_the_various_TDMA_slot_allocation_algorithms_and_synchronization_information_See_ITU-R_M.1371-1_for_more_information.";
CM_ SG_ 2448953086 COG "The_direction_of_the_path_over_ground_actually_followed_by_a_vessel.";
CM_ SG_ 2448953086 TimeStamp "0-59=UTC_second_when_report_was_generated,_60=time_stamp_not_available(default),_61=Posing_system_is_in_manual_input_mode,_62=Electronic_Pos_fixing_system_operates_in_Est(dead_reckoning)mode,_63=Posing_system_is_inoperative_See_ITU-R_M.1371-1_for_m";
CM_ SG_ 2448953086 RAIMflag "0_=_RAIM_not_in_use_(default),_1_=_RAIM_in_use_See_ITU-R_M.1371-1_for_more_information.";
CM_ SG_ 2448953086 PosAccuracy "0=low_accuracy>10m_such_as_nondifferential_GNSS_(default),__1=high_accuracy_<10m_such_as_DGNSS_See_ITU-R_M.1371-1_for_more_information.";
CM_ SG_ 2448953086 UserID "Number_of_route,_waypoint,_event,_mark,_etc.";
CM_ SG_ 2448953086 RepeatIndicator "Used_by_the_repeater_to_indicate_how_many_times_a_message_has_been_repeated_(range_of_0_to_3)._0_=_Default_1_=_First_retransmission_2_=_Second_retransmission_3_=_Final_retransmission_See_ITU-R_M.1371-1_for_more_information.";
CM_ SG_ 2448953086 MsgID "Message_Identifier_(range_of_0_to_63)._See_ITU-R_M.1371-1_for_more_information.";
CM_ BO_ 2650473982 "This_parameter_group_provides_data_associated_with_ITU-R_M1371_Msg_8_Binary_Broadcast_Msg_supporting_broadcast_communication_of_binary_dataAn_AIS_device_may_generate_this_parameter_group_either_upon_receiving_a_VHF_data_link_Msg_8,or_upon_receipt_of_an_";
CM_ SG_ 2650473982 NumberOfBitsInBinaryDataField "Number_of_route,_waypoint,_event,_mark,_etc.";
CM_ SG_ 2650473982 AISTransceiverInformation "0_=_Channel_A_VDL_reception,_1_=_Channel_B_VDL_reception,_2_=_Channel_A_VDL_transmission,_3_=_Channel_B_VDL_transmission,_4_=_Own_information_not_broadcast,_5-31_=_Reserved.";
CM_ SG_ 2650473982 SourceID "Number_of_route,_waypoint,_event,_mark,_etc.";
CM_ SG_ 2650473982 RepeatIndicator "Used_by_the_repeater_to_indicate_how_many_times_a_message_has_been_repeated_(range_of_0_to_3)._0_=_Default_1_=_First_retransmission_2_=_Second_retransmission_3_=_Final_retransmission_See_ITU-R_M.1371-1_for_more_information.";
CM_ SG_ 2650473982 MsgID "Message_Identifier_(range_of_0_to_63)._See_ITU-R_M.1371-1_for_more_information.";
CM_ BO_ 2650475774 "This_parameter_group_provides_data_associated_with_ITU-R_M1371_Msg_16_Assigned_Mode_Cmd_Msg_for_assigning_specific_behavior_by_a_competent_authorityAn_AIS_device_may_generate_this_parameter_group_either_upon_receiving_a_VHF_data_link_Msg_16,or_upon_rece";
CM_ SG_ 2650475774 IncrementB "Number_of_route,_waypoint,_event,_mark,_etc.";
CM_ SG_ 2650475774 OffsetB "Number_of_route,_waypoint,_event,_mark,_etc.";
CM_ SG_ 2650475774 DestinationIDB "Number_of_route,_waypoint,_event,_mark,_etc.";
CM_ SG_ 2650475774 IncrementA "Number_of_route,_waypoint,_event,_mark,_etc.";
CM_ SG_ 2650475774 OffsetA "Number_of_route,_waypoint,_event,_mark,_etc.";
CM_ SG_ 2650475774 DestinationIDA "Number_of_route,_waypoint,_event,_mark,_etc.";
CM_ SG_ 2650475774 AISTransceiverInformation "0_=_Channel_A_VDL_reception,_1_=_Channel_B_VDL_reception,_2_=_Channel_A_VDL_transmission,_3_=_Channel_B_VDL_transmission,_4_=_Own_information_not_broadcast,_5-31_=_Reserved.";
CM_ SG_ 2650475774 SourceID "Number_of_route,_waypoint,_event,_mark,_etc.";
CM_ SG_ 2650475774 RepeatIndicator "Used_by_the_repeater_to_indicate_how_many_times_a_message_has_been_repeated_(range_of_0_to_3)._0_=_Default_1_=_First_retransmission_2_=_Second_retransmission_3_=_Final_retransmission_See_ITU-R_M.1371-1_for_more_information.";
CM_ SG_ 2650475774 MsgID "Message_Identifier_(range_of_0_to_63)._See_ITU-R_M.1371-1_for_more_information.";
CM_ BO_ 2565406462 "Acknowledgment_Message";
CM_ SG_ 2565406462 ParameterGroupNumber "PGN_which_is_requested_by_Request2_message";
CM_ SG_ 2565406462 GroupFunctionValue "Group_Function_of_PGN_being_acknowledged._This_field_identifies_for_a_device_the_specific_group_function_of_a_PGN_being_acknowledged_or_declined.__This_field_is_not_used_if_the_PGN_being_acknowledged_or_declined_is_not_a_group_function_PGN.";
CM_ BO_ 2382238206 "purpose_of_this_PGN_is_to_group_three_fundamental_vectors_related_to_vessel_motion,_-Speed_and_heading_referenced_to_water_-Speed_and_course_referenced_to_ground_-Current_speed_and_flow_direction_Products_that_are_primary_form_of_navigation_would_";
CM_ SG_ 2382238206 Set "Direction_towards_which_current_flows.__Degrees_relative_to_True_North.";
CM_ SG_ 2382238206 Heading "The_horizontal_direction_in_which_a_ship_actually_points_or_heads_at_any_instant,_expressed_in_angular_units_from_a_reference_direction,_usually_from_000_at_the_reference_direction_clockwise_through_359_degrees.";
CM_ SG_ 2382238206 CourseOverGround "The_direction_of_the_path_over_ground_actually_followed_by_a_vessel.";
CM_ SG_ 2382238206 SID "An_upward_counting_number_used_to_tie_related_information_together_between_different_PGNs.For_example,SID_would_be_used_to_tie_together_COG,SOG_and_RAIM_values_to_a_given_Pos.255=no_valid_Pos_fix_to_tie_it_to.Range_0_to_250_for_valid_Pos_fixes.";
CM_ SG_ 2382238206 Set_COG_HeadingRef "0_=_True,__1_=_Magnetic,_2_=_Error,_3_=_Null";
CM_ SG_ 2382238206 DataMode "0x0_=_Autonomous_mode,__0x1_=_Differential,_enhanced_mode,_0x2_=_Estimated_mode,_0x3_=_Simulator_mode,_0x4_=_Manual_mode,_0xE_=_Error,_0xF_=_Data_not_available";
CM_ BO_ 2583172350 "Local_geodetic_datum_and_datum_offsets_from_a_reference_datum_This_PGN_is_used_to_define_the_datum_to_which_a_position_location_output_by_the_same_device_in_other_PGNs_is_referenced";
CM_ SG_ 2583172350 ReferenceDatum "Length_specified_by_PGN_field_definition.";
CM_ SG_ 2583172350 LocalDatum "4-character_code_for_datum_currently_being_output_for_Pos_solution.datum's_are_defined_in_IHO_Publication_S-60,Appendices_B_and_C.first_three_chars_are_datum_ID_as_per_IHO_tables.fourth_char_is_local_datum_subdivision_code.A_null_char_indicates_datum_subd";
CM_ BO_ 2449150206 "This_PGN_provides_Digital_Selective_CallingDSCdata_according_to_ITU_M493-9_with_optional_expansion_according_to_ITU_M821-1_DSC_is_a_paging_system_that_is_used_to_automate_distress_alerts_sent_over_terrestrial_communication_systems_such_as_VHF,MF_and";
CM_ SG_ 2449150206 VarNbrOfFldsFld22RepExpFldData "Name_of_place,_route,_waypoint,_destination,_vessel,_vehicle,_etc.";
CM_ SG_ 2449150206 DSCExpansionFieldData "Name_of_place,_route,_waypoint,_destination,_vessel,_vehicle,_etc.";
CM_ SG_ 2449150206 TelephoneNumber "Name_of_place,_route,_waypoint,_destination,_vessel,_vehicle,_etc.";
CM_ SG_ 2449150206 ProposedTxFrequencyChannel "Length_specified_by_PGN_field_definition.";
CM_ SG_ 2449150206 ProposedRxFrequencyChannel "Length_specified_by_PGN_field_definition.";
CM_ SG_ 2449150206 MMSIOfShipInDistress "Length_specified_by_PGN_field_definition.";
CM_ SG_ 2449150206 CallingTxFrequencyChannel "Length_specified_by_PGN_field_definition.";
CM_ SG_ 2449150206 CallingRxFrequencyChannel "Length_specified_by_PGN_field_definition.";
CM_ SG_ 2449150206 DSCMsgAddress "Individual_characters_having_only_decimal_values_in_range_0_to_127_for_DSC_symbols_defined_by_ITU-R_M.493_are_used_to_code_address_geographic_area_as_defined_in_ITU-R_M.493-9_Section_5.This_may_represent_an_individual_MMSI,a_group_MMSI,or_a_geographic_are";
CM_ SG_ 2449150206 DSCCategorySymbol "Integer_numbers_within_the_range_000_to_127_representing_DSC_Symbols_defined_by_ITU-R_M.493_Table_3_for:_Phasing_and_Unique_Functions_Format_Specifier_Category_Nature_of_Distress_First_Telecommand_Second_Telecommand";
CM_ SG_ 2449150206 DSCFormatSymbol "Integer_numbers_within_the_range_000_to_127_representing_DSC_Symbols_defined_by_ITU-R_M.493_Table_3_for:_Phasing_and_Unique_Functions_Format_Specifier_Category_Nature_of_Distress_First_Telecommand_Second_Telecommand";
CM_ BO_ 2583301630 "This_PGN_provides_a_means_to_pass_Diff_GNSS_corrections_between_NMEA_2000_devicesPassing_DGNSS_data_this_way_allows_for_more_flexibility_than_traditional_methodsOne_Diff_correction_receiver_could_supply_multiple_GNSS_receiversMultiple_Diff_correction_r";
CM_ SG_ 2583301630 IOD "Number_of_route,_waypoint,_event,_mark,_etc.";
CM_ SG_ 2583301630 UDRE "Dependent_upon_PG_Field_definition.";
CM_ SG_ 2583301630 SatelliteID "0_=_value_not_used,_1-32_=_GPS,_33-64_=_SBAS,Satellite,Based_Augmentation_System(ie_WAAS)_65-96_=_GLONASS._For_GLONASS,satellites_are_identified_by_64+satellite_slot_number.slot_numbers_are_1_through_24_for_full_GLONASS_constellation_of_24_satellite";
CM_ SG_ 2583301630 StationHealth "0x00_=_Not_Working,_0x01_=_Unmonitored,_0x02_=_Healthy_&_Operational,_0x03_=_Healthy_&_in_Test_Mode,_0x04_=_In_Test_Mode_-_DO_NOT_USE,_0x05_-_0x15_=_Reserved";
CM_ SG_ 2583301630 ReferenceStationType "Reference_Station_Type.__0x0=GP";
CM_ SG_ 2583301630 ReferenceStationID "Reference_Station_ID.__Reference_Station_number_as_provided_by_the_Service_Provider.[Reference_document_required]";
CM_ SG_ 2583301630 SequenceID_ "An_upward_counting_number_used_to_tie_related_information_together_between_different_PGNs.For_example,SID_would_be_used_to_tie_together_COG,SOG_and_RAIM_values_to_a_given_Pos.255=no_valid_Pos_fix_to_tie_it_to.Range_0_to_250_for_valid_Pos_fixes.";
CM_ BO_ 2583499518 "Current_station_measurement_data_including_station_location,_numeric_identifier,_and_name";
CM_ SG_ 2583499518 StationNameString "Name_of_place,_route,_waypoint,_destination,_vessel,_vehicle,_etc.";
CM_ SG_ 2583499518 StationIDString "Name_of_place,_route,_waypoint,_destination,_vessel,_vehicle,_etc.";
CM_ SG_ 2583499518 CurrentFlowDirection "Direction_towards_which_current_flows.__Degrees_relative_to_True_North.";
CM_ SG_ 2583499518 MeasurementDepth "Water_depth_measured_from_the_water_surface";
CM_ SG_ 2583499518 MeasurementTime "24_hour_clock,_0_=__midnight,__time_is_in_UTC";
CM_ SG_ 2583499518 MeasurementDate "Days_since_January_1,_1970,___Date_is_relative_to_UTC_Time.";
CM_ SG_ 2583499518 State "000_=_Flood,__001_=_Slack,_010_=_Ebb,_011_=_Reserved,_100_=_Reserved,_101_=_Reserved,_110_=_Error,_111_=_Unavailable,_Unknown";
CM_ SG_ 2583499518 Mode "Range_Residual_used_in_position_calculation_or_range_residuals_were_calculated_after_the_position.___0=range_residuals_were_used_to_calculate_dat";
CM_ BO_ 2381906942 "This_PGN_provides_the_magnitude_of_position_error_perpendicular_to_the_desired_course";
CM_ SG_ 2381906942 XTE "Cross-track-error_of_a_route.__'-'_=_Left_of_track,_need_to_steer_right";
CM_ SG_ 2381906942 NavigationTerminated "MSB/LSB:__00_=_[No,_Off,_Disabled,_Reset,_'0'],_01_=_[Yes,_On,_Enabled,_Set,_'1'],_10_=_Error,_11=_[Unavailable,_Unknown]";
CM_ SG_ 2381906942 XTEMode "0x0_=_Autonomous_mode,__0x1_=_Differential,_enhanced_mode,_0x2_=_Estimated_mode,_0x3_=_Simulator_mode,_0x4_=_Manual_mode,_0xE_=_Error,_0xF_=_Data_not_available";
CM_ SG_ 2381906942 SID "An_upward_counting_number_used_to_tie_related_information_together_between_different_PGNs.For_example,SID_would_be_used_to_tie_together_COG,SOG_and_RAIM_values_to_a_given_Pos.255=no_valid_Pos_fix_to_tie_it_to.Range_0_to_250_for_valid_Pos_fixes.";
CM_ BO_ 2314732286 "This_PGN_is_a_single_frame_PGN_that_provides_Course_Over_GroundCOGand_Speed_Over_GroundSOG_Being_a_single_frame_Msg,as_opposed_to_other_PGNs_that_include_COG_and_SOG_and_are_defined_as_multi-packet,this_PGN_lends_itself_to_being_transmitted_more_f";
CM_ SG_ 2314732286 CourseOverGround "The_direction_of_the_path_over_ground_actually_followed_by_a_vessel.";
CM_ SG_ 2314732286 COGReference "0_=_True,__1_=_Magnetic,_2_=_Error,_3_=_Null";
CM_ SG_ 2314732286 SID "An_upward_counting_number_used_to_tie_related_information_together_between_different_PGNs.For_example,SID_would_be_used_to_tie_together_COG,SOG_and_RAIM_values_to_a_given_Pos.255=no_valid_Pos_fix_to_tie_it_to.Range_0_to_250_for_valid_Pos_fixes.";
CM_ BO_ 2650475006 "This_parameter_group_provides_data_associated_with_ITU-R_M1371_Msg_12_Addressed_Safety_Related_Msg_supporting_addressed_communication_of_safety_related_dataAn_AIS_device_may_generate_this_parameter_group_either_upon_receiving_a_VHF_data_link_Msg_12,or_u";
CM_ SG_ 2650475006 SafetyRelatedText "Name_of_place,_route,_waypoint,_destination,_vessel,_vehicle,_etc.";
CM_ SG_ 2650475006 RetransmitFlag "0=No_retransmission,_1=retransmitted._See_ITU-R_M.1371-1_for_more_information.";
CM_ SG_ 2650475006 DestinationID "Number_of_route,_waypoint,_event,_mark,_etc.";
CM_ SG_ 2650475006 SequenceNumber_ "Range_0-3_See_ITU-R_M.1371-1_for_more_information.";
CM_ SG_ 2650475006 AISTransceiverInformation "0_=_Channel_A_VDL_reception,_1_=_Channel_B_VDL_reception,_2_=_Channel_A_VDL_transmission,_3_=_Channel_B_VDL_transmission,_4_=_Own_information_not_broadcast,_5-31_=_Reserved.";
CM_ SG_ 2650475006 SourceID "Number_of_route,_waypoint,_event,_mark,_etc.";
CM_ SG_ 2650475006 RepeatIndicator "Used_by_the_repeater_to_indicate_how_many_times_a_message_has_been_repeated_(range_of_0_to_3)._0_=_Default_1_=_First_retransmission_2_=_Second_retransmission_3_=_Final_retransmission_See_ITU-R_M.1371-1_for_more_information.";
CM_ SG_ 2650475006 MsgID "Message_Identifier_(range_of_0_to_63)._See_ITU-R_M.1371-1_for_more_information.";
CM_ BO_ 2650473470 "This_parameter_group_provides_data_associated_with_ITU-R_M1371_Msg_6_Addressed_Binary_Msg_supporting_address_communication_of_binary_dataAn_AIS_device_may_generate_this_parameter_group_either_upon_receiving_a_VHF_data_link_Msg_6,or_upon_receipt_of_an_IS";
CM_ SG_ 2650473470 NumberOfBitsInBinaryDataField "Number_of_route,_waypoint,_event,_mark,_etc.";
CM_ SG_ 2650473470 RetransmitFlag "0=No_retransmission,_1=retransmitted._See_ITU-R_M.1371-1_for_more_information.";
CM_ SG_ 2650473470 DestinationID "Number_of_route,_waypoint,_event,_mark,_etc.";
CM_ SG_ 2650473470 SequenceNumber_ "Range_0-3_See_ITU-R_M.1371-1_for_more_information.";
CM_ SG_ 2650473470 AISTransceiverInformation "0_=_Channel_A_VDL_reception,_1_=_Channel_B_VDL_reception,_2_=_Channel_A_VDL_transmission,_3_=_Channel_B_VDL_transmission,_4_=_Own_information_not_broadcast,_5-31_=_Reserved.";
CM_ SG_ 2650473470 SourceID "Number_of_route,_waypoint,_event,_mark,_etc.";
CM_ SG_ 2650473470 RepeatIndicator "Used_by_the_repeater_to_indicate_how_many_times_a_message_has_been_repeated_(range_of_0_to_3)._0_=_Default_1_=_First_retransmission_2_=_Second_retransmission_3_=_Final_retransmission_See_ITU-R_M.1371-1_for_more_information.";
CM_ SG_ 2650473470 MsgID "Message_Identifier_(range_of_0_to_63)._See_ITU-R_M.1371-1_for_more_information.";
CM_ BO_ 2650473726 "This_parameter_group_provides_data_associated_with_ITU-R_M1371_Msgs_7_Binary_Acknowledge_Msg_and_13_Safety_Related_Acknowledge_MsgMsg_7_acknowledges_receipt_of_Msg_6_while_Msg_13_acknowledges_receipt_of_Msg_14An_AIS_device_may_generate_this_parameter_g";
CM_ SG_ 2650473726 SequenceNumberForIDn "Range_0-3_See_ITU-R_M.1371-1_for_more_information.";
CM_ SG_ 2650473726 SequenceNumberForID1 "Range_0-3_See_ITU-R_M.1371-1_for_more_information.";
CM_ SG_ 2650473726 DestinationID1 "Number_of_route,_waypoint,_event,_mark,_etc.";
CM_ SG_ 2650473726 AISTransceiverInformation "0_=_Channel_A_VDL_reception,_1_=_Channel_B_VDL_reception,_2_=_Channel_A_VDL_transmission,_3_=_Channel_B_VDL_transmission,_4_=_Own_information_not_broadcast,_5-31_=_Reserved.";
CM_ SG_ 2650473726 SourceID "Number_of_route,_waypoint,_event,_mark,_etc.";
CM_ SG_ 2650473726 RepeatIndicator "Used_by_the_repeater_to_indicate_how_many_times_a_message_has_been_repeated_(range_of_0_to_3)._0_=_Default_1_=_First_retransmission_2_=_Second_retransmission_3_=_Final_retransmission_See_ITU-R_M.1371-1_for_more_information.";
CM_ SG_ 2650473726 MsgID "Message_Identifier_(range_of_0_to_63)._See_ITU-R_M.1371-1_for_more_information.";
CM_ BO_ 2516387838 "Environmental_Conditions_contains_Temperature,_Humidity,_and_Atmospheric_Pressure__This_PGN_is_a_rework_of_PGN_130310_and_is_to_be_used_for_new_designs";
CM_ SG_ 2516387838 HumidityInstance "0x00_=_Inside_Humidity,_0x01_=_Outside_Humidity,_0x02_=_reserved,_0x03_=_Data_Not_Available";
CM_ SG_ 2516387838 TempInstance "0x00_=_Sea_Temperature,_0x01_=_Outside_Temperature,_0x02_=_Inside_Temperature,_0x03_=_Engine_Room_Temperature,_0x04_=_Main_Cabin_Temperature,_0x05_=_Reserve,_thru_0x3E_=_Reserve,_0x3F_=_Data_Not_Available";
CM_ SG_ 2516387838 SequenceID_ "An_upward_counting_number_used_to_tie_related_information_together_between_different_PGNs.For_example,SID_would_be_used_to_tie_together_COG,SOG_and_RAIM_values_to_a_given_Pos.255=no_valid_Pos_fix_to_tie_it_to.Range_0_to_250_for_valid_Pos_fixes.";
CM_ BO_ 2582648062 "Provides_product_information_onto_network_that_could_be_important_for_determining_quality_of_data_coming_from_this_productEach_field_must_be_provided_if_data_is_typically_available_from_such_a_productAt_Min_NMEA_2000_Version,NMEA_Manufacturers_Product_";
CM_ SG_ 2582648062 ManufacturersModelSerialCode "Length_specified_by_PGN_field_definition.";
CM_ SG_ 2582648062 ManufacturersModelVersion "Length_specified_by_PGN_field_definition.";
CM_ SG_ 2582648062 ManufacturersSoftwareVersionCode "Length_specified_by_PGN_field_definition.";
CM_ SG_ 2582648062 ManufacturersModelID "Length_specified_by_PGN_field_definition.";
CM_ SG_ 2582648062 NMEAManufacturersProductCode "Number_of_route,_waypoint,_event,_mark,_etc.";
CM_ SG_ 2582648062 NMEA2000DatabaseVersion "Number_of_route,_waypoint,_event,_mark,_etc.";
CM_ BO_ 2582648574 "Free-form_alphanumeric_fields_describing_the_installation__eg,_starboard_engine_room_location_of_the_device_and_installation_notes_eg,_calibration_data";
CM_ BO_ 2582576894 "Transmit/Receive_PGN_List_Group_type_of_function_is_defined_by_first_fieldMsg_will_be_a_Transmit_Receive_PGN_List_group_functionThese_are_defined_as_follows:_Transmit_PGN_List_group_function:This_Msg_contains_a_list_of_Transmitted_PGNs_that_are_suppo";
CM_ SG_ 2582576894 VrblNmbrOfFldsFldNmber2Repeated2 "24-bit_Parameter_Group_Number_(PGN)_expressed_in_binary,_LSB_is_transmitted_first";
CM_ SG_ 2582576894 FirstPGNSupported2 "24-bit_Parameter_Group_Number_(PGN)_expressed_in_binary,_LSB_is_transmitted_first";
CM_ SG_ 2582576894 VrblNmbrOfFldsFldNmber2Repeated "24-bit_Parameter_Group_Number_(PGN)_expressed_in_binary,_LSB_is_transmitted_first";
CM_ SG_ 2582576894 FirstPGNSupported "24-bit_Parameter_Group_Number_(PGN)_expressed_in_binary,_LSB_is_transmitted_first";
CM_ SG_ 2582576894 GrpFnctnTrnsmtAndReceivePGNList "0_=_Transmit_PGN_List_Message,__1_=_Receive_PGN_List_Message";
BA_DEF_ SG_  "SystemSignalLongSymbol" STRING ;
BA_DEF_ BO_  "SystemMessageLongSymbol" STRING ;
BA_DEF_DEF_  "SystemSignalLongSymbol" "";
BA_DEF_DEF_  "SystemMessageLongSymbol" "";
BA_ "SystemMessageLongSymbol" BO_ 2583368190 "AIS_Class_B_CS_Static_Data_Report_Part_A";
BA_ "SystemMessageLongSymbol" BO_ 2583368446 "AIS_Class_B_CS_Static_Data_Report_Part_B";
BA_ "SystemSignalLongSymbol" SG_ 2582779646 Estimated_Battery_Temp_When_No_S "Estimated_Battery_Temp_When_No_Sensor";
BA_ "SystemSignalLongSymbol" SG_ 2650476286 Addressed_or_Broadcast_Message_I "Addressed_or_Broadcast_Message_Indicator";
BA_ "SystemSignalLongSymbol" SG_ 2583368446 Reference_Point_Position_from_St "Reference_Point_Position_from_Starboard";
BA_ "SystemSignalLongSymbol" SG_ 2583368446 Reference_Point_Position_Aft_of_ "Reference_Point_Position_Aft_of_Bow";
VAL_ 2565799678 IndustryGroup 6 "Reserved_for_SAE" 7 "Reserved_for_SAE" 5 "IndustrialProcessCtrlStationary" 4 "Marine" 3 "Construction" 2 "Agricultural_and_Forestry" 1 "On-Highway" 0 "Global" ;
VAL_ 2565799678 Function 127 "Reserved" 126 "Reserved" 125 "Reserved" 124 "Reserved" 123 "Reserved" 122 "Reserved" 121 "Reserved" 120 "Reserved" 119 "Reserved" 118 "Reserved" 117 "Reserved" 116 "Reserved" 115 "Reserved" 114 "Reserved" 113 "Reserved" 112 "Reserved" 111 "Reserved" 110 "Reserved" 109 "Reserved" 108 "Reserved" 107 "Reserved" 106 "Reserved" 105 "Reserved" 104 "Reserved" 103 "Reserved" 102 "Reserved" 101 "Reserved" 42 "Water_Pump_Control" 41 "Lighting_-_Operator_Controls" 40 "Seat_Control" 39 "Ignition_Control_Module" 38 "Tire_Pressure_Control" 37 "Cab_Controller" 36 "Pneumatic_-_System_Controller" 35 "Suspension_-_System_Controller" 34 "Hydraulic_Pump_Controller" 33 "System_Monitor" 32 "Headway_Controller" 31 "Propulsion_Battery_Charger" 30 "Management_Computer" 29 "Virtual_Terminal_in_cab" 28 "Off_Vehicle_Gateway" 27 "Power_TakeOff_Secondary_or_Front" 26 "Body_Controller" 25 "Network_Interconnect_ECU" 24 "Vehicle_Security" 23 "Vehicle_Navigation" 22 "Aerodynamic_Control" 21 "Cab_Climate_Control" 20 "Trip_Recorder" 19 "Instrument_Cluster" 18 "Suspension_-_Drive_Axle" 17 "Suspension_-_Steer_Axle" 16 "Steering_Controller" 15 "Fuel_System" 14 "Cruise_Control" 13 "Retarder_-_Driveline" 12 "Retarder_-_Engine" 11 "Brakes_-_Drive_Axle" 10 "Brakes_-_Steer_Axle" 9 "Brakes_-_System_Controller" 8 "Axle_-_Drive" 7 "Axle_-_Steering" 6 "Power_TakeOff_-_Main_or_Rear" 5 "Shift_Control/Console" 4 "Battery_Pack_Monitor" 3 "Transmission" 2 "Electric_Propulsion_Control" 1 "Auxiliary_Power_Unit_APU" 0 "Engine" 100 "Reserved" 99 "Reserved" 98 "Reserved" 97 "Reserved" 96 "Reserved" 95 "Reserved" 94 "Reserved" 93 "Reserved" 92 "Reserved" 91 "Reserved" 90 "Reserved" 89 "Reserved" 88 "Reserved" 87 "Reserved" 86 "Reserved" 85 "Reserved" 84 "Reserved" 83 "Reserved" 82 "Reserved" 81 "Reserved" 80 "Reserved" 79 "Reserved" 78 "Reserved" 77 "Reserved" 76 "Reserved" 75 "Supplemental_Fan" 74 "Lubrication_System" 73 "Rollover_Detection_Control" 72 "Coolant_Valve_Controller" 71 "Transfer_Case_Control" 70 "Auxiliary_Regeneration_Device" 69 "Engine_Emission_Aftertreatement_System" 68 "Aftertreatment_system_gas_measurement" 67 "Electrical_System_Controller" 66 "I/O_Controller" 65 "Gas_Flow_Measurement" 64 "Endurance_Braking" 63 "Engine_Valve_Controller" 62 "On-Board_Diagnostic_Unit" 61 "File_Server/Printer" 60 "Cab_Display" 59 "Starter" 58 "Fan_Drive_Control" 57 "Steering_Column_Unit" 56 "Communications_Unit,_Radio" 55 "Communications_Unit,_Satellite" 54 "Communications_Unit,_Cellular" 53 "Alternator/Charging_System" 52 "Chassis_Controller" 51 "Forward-Looking_Collision_Warning_System" 50 "Auxiliary_Heater" 49 "Clutch/Converter_Control" 48 "Ramp_Control" 47 "Information_System_Controller" 46 "Oil_Sensor_Unit" 45 "Vehicle_Dynamic_Stability_Control" 44 "Exhaust_Emission_Control" 43 "Transmission_Display" ;
VAL_ 2565799678 VehicleSystem 0 "Non-specific_System" 127 "Not_Available" ;
VAL_ 2565799678 VehicleSystem5 127 "Not_Available" 0 "Ind._Process_Control_Stationary" ;
VAL_ 2565799678 VehicleSystem4 125 "Entertainment" 120 "Display" 85 "External_Environment" 75 "Sensor_Communication_Interface" 35 "Electrical_Generation" 100 "Deck,_Cargo_and_Fishing_Equipment" 90 "Internal_Environment" 80 "Instrumentation/General_Systems_deprecate" 70 "Communications" 60 "Navigation" 50 "Propulsion" 40 "Steering_and_Control_Surfaces" 30 "Electrical_Distribution" 25 "Inter/Intranetwork_Device" 20 "Safety_Systems" 10 "System_Tools" 127 "Not_Available" 0 "Non-specific_System" ;
VAL_ 2565799678 VehicleSystem3 8 "Grader" 7 "Four_Wheel_Drive_Loader" 6 "Forklift" 5 "Excavator" 4 "Crawler" 3 "Backhoe" 2 "Articulated_Dump_Truck" 1 "Skid_Steer_Loader" 127 "Not_Available" 0 "Non-specific_System" ;
VAL_ 2565799678 VehicleSystem2 16 "Skidder" 15 "Earth_Work" 14 "Special_Crops" 13 "Powered_Auxiliary_Device" 12 "Farm_Yard_Operations" 11 "Transport/Trailer" 10 "Irrigation" 9 "Forage" 8 "Root_Harvesters" 7 "Harvesters" 6 "Sprayers" 5 "Fertilizers" 4 "Planters/Seeders" 3 "Secondary_Tillage" 2 "Tillage" 1 "Tractor" 127 "Not_Available" 0 "Non-specific_System" ;
VAL_ 2565799678 VehicleSystem1 2 "Trailer" 1 "Tractor" 127 "Not_Available" 0 "Non-specific_System" ;
VAL_ 2632777470 PGNumber 255 "NotAvailable" ;
VAL_ 2632777470 ControlByte 24 "EAbort" 23 "EEoMACK" 22 "EDPO" 21 "ECTS" 20 "ERTS" 255 "Abort" 32 "BAM" 19 "EoMA" 17 "CTS" 16 "RTS" ;
VAL_ 2315059966 WindReference 7 "Null" 6 "Error" 5 "Reserved" 3 "True_boat_referenced" 2 "Apparent" 1 "Magnetic" 0 "True_referenced_to_North" ;
VAL_ 2315059966 SequenceID_ 255 "nVldPsFxTTItTRng0T250FrVldPstnFx" ;
VAL_ 2381646846 SID 255 "nVldPsFxTTItTRng0T250FrVldPstnFx" ;
VAL_ 2314277630 HeadingSensorReference 3 "Null" 2 "Error" 1 "Magnetic" 0 "True" ;
VAL_ 2314277630 SID 255 "nVldPsFxTTItTRng0T250FrVldPstnFx" ;
VAL_ 2515667454 EngInstance 255 "Not_available" 254 "Error" 253 "Reserve" 1 "DlEngStrBrdTStrnStrbrdNInstncNWh" 0 "SingleEngDualEnginePort" ;
VAL_ 2314339838 TransGear 3 "[Unavailable,_Unknown]" 2 "Reverse" 1 "Neutral" 0 "Forward" ;
VAL_ 2314339838 TransInstance 255 "Not_available" 254 "Error" 253 "Reserve" 1 "DlEngStrBrdTStrnStrbrdNInstncNWh" 0 "SingleEngDualEnginePort" ;
VAL_ 2314602750 BearingReference 3 "Releative" 2 "Error" 1 "Magnetic" 0 "True" ;
VAL_ 2314602750 SequenceID_ 255 "nVldPsFxTTItTRng0T250FrVldPstnFx" ;
VAL_ 2314602750 UTCOfFix 0 "midnight,__time_is_in_UTC" ;
VAL_ 2314276350 Directionder 2 "Move_to_port" 1 "Move_to_starboard" 0 "No_Order" ;
VAL_ 2314276350 RudderInstance 255 "Not_available" 254 "Error" 253 "Reserve" 1 "DlEngStrBrdTStrnStrbrdNInstncNWh" 0 "SingleEngDualEnginePort" ;
VAL_ 2650543614 NavMethodInLegAfterWP 3 "Null" 2 "Error" 1 "Rhumb_Line_calculations" 0 "Great_Circle_calculations" ;
VAL_ 2583300606 SVIDOfMostLikelyFailedSat 96 "GLONASSFrGLONASSStlltsArIdntfdBy" 64 "SBASStlltBsdAgmentationSystem65" 1 "GPS,_" 33 "0" 0 "not" ;
VAL_ 2583300606 IntegrityFlag 3 "UnsfMnsRcvrDsNtHvThisCapability" 2 "Caution" 1 "Safe" 0 "No_Integrity_checking,*" ;
VAL_ 2583300606 SequenceID_ 255 "nVldPsFxTTItTRng0T250FrVldPstnFx" ;
VAL_ 2583299838 SID 255 "nVldPsFxTTItTRng0T250FrVldPstnFx" ;
VAL_ 2583301118 SequenceID_ 255 "nVldPsFxTTItTRng0T250FrVldPstnFx" ;
VAL_ 2381841918 ReferenceStationTypeN 15 "Null" 14 "Error" 13 "Reserved" 1 "GLONASS_" ;
VAL_ 2381841918 ReferenceStationType1 15 "Null" 14 "Error" 13 "Reserved" 1 "GLONASS_" ;
VAL_ 2381841918 Integrity 3 "UnsfMnsRcvrDsNtHvThisCapability" 2 "Caution" 1 "Safe" 0 "No_Integrity_checking,*" ;
VAL_ 2381841918 MethodGNSS 15 "NllPrcsGNSSMnsNDlbrtDgrdtnAndHgh" 14 "Error" 9 "Reserved" 8 "Simulate_mode" 7 "Manual_Input" 6 "Estimated_DR_mode" 5 "RTK_Float" 4 "RTK_Fixed_Integer" 3 "Precise_GNSS*" 2 "DGNSS_fix" 1 "GNSS_fix" 0 "no_GPS" ;
VAL_ 2381841918 TypeOfSystem_ 21 "Reserved_for_future_combinations" 4 "GPS+SBAS+GLONASS" 0 "-" 3 "GPS+SBASWAAS" 2 "GPS+GLONASS" 1 "GLONASS" 0 "GPS" ;
VAL_ 2381841918 PosTime 0 "midnight,__time_is_in_UTC" ;
VAL_ 2381841918 SID 255 "nVldPsFxTTItTRng0T250FrVldPstnFx" ;
VAL_ 2583301886 DiffOperationMode 15 "No_Selection" 14 "Error" 3 "Reserved" 2 "Auto_Range" 1 "Auto_Power" 0 "Manual" ;
VAL_ 2583301886 DiffSource 15 "No_Selection" 14 "Error" 8 "Reserved" 7 "Other_Satellite" 6 "SBAS" 5 "Other_Ground-based_Radio" 4 "AIS" 3 "FM_Subcarrier" 2 "MSK_Beacon" 1 "Loran_Communications" 0 "Auto_Select" ;
VAL_ 2583301886 SerialInterfaceDetectionMode 7 "Null" 6 "Error" 2 "Reserved" 1 "Manual_bit_rate_set" 0 "Auto_bit_rate_set" ;
VAL_ 2583301886 SerialInterfaceBitRate 31 "Null" 30 "Error" 29 "Reserved" 12 "57600bps," 13 "11" 0 "10" 0 "9" 0 "8" 0 "7" 0 "6" 0 "5" 0 "4" 0 "3" 0 "2" 0 "1" 0 "0" ;
VAL_ 2583302142 DiffSource 15 "No_Selection" 14 "Error" 8 "Reserved" 7 "Other_Satellite" 6 "SBAS" 5 "Other_Ground-based_Radio" 4 "AIS" 3 "FM_Subcarrier" 2 "MSK_Beacon" 1 "Loran_Communications" 0 "Auto_Select" ;
VAL_ 2583302142 UsedAsCorrectionSource 3 "[Unavailable,_Unknown]" 2 "Error" 1 "[Yes,_On,_Enabled,_Set,_'1']" 0 "[No,_Off,_Disabled,_Reset,_'0']" ;
VAL_ 2583302142 DiffSignalDetectionMode 7 "Null" 6 "Error" 2 "Reserved" 1 "Manual_bit_rate_set" 0 "Auto_bit_rate_set" ;
VAL_ 2583302142 DiffSignalBitRate 3 "200bps" 2 "100bps" 1 "50bps" 0 "25bps" 31 "Null" 30 "Error" 29 "Reserved" 12 "57600bps," 13 "11" 0 "10" 0 "9" 0 "8" 0 "7" 0 "6" 0 "5" 0 "4" ;
VAL_ 2583302142 StationType 15 "Null" 14 "Error" 13 "Reserved" 1 "GLONASS_" ;
VAL_ 2583302142 SID 255 "nVldPsFxTTItTRng0T250FrVldPstnFx" ;
VAL_ 2583299070 OpMode 7 "Null" 6 "Error" 4 "Reserved" 3 "Auto" 2 "3D" 1 "2D" 0 "1D" ;
VAL_ 2583299070 SetMode 7 "Null" 6 "Error" 4 "Reserved" 3 "Auto" 2 "3D" 1 "2D" 0 "1D" ;
VAL_ 2583299070 SID 255 "nVldPsFxTTItTRng0T250FrVldPstnFx" ;
VAL_ 2583298814 UseAntennaAltitudeFor2DMode 3 "[Unavailable,_Unknown]" 2 "Error" 1 "[Yes,_On,_Enabled,_Set,_'1']" 0 "[No,_Off,_Disabled,_Reset,_'0']" ;
VAL_ 2583298814 Pos_VelocityFilter 2 "Error" 1 "[Yes,_On,_Enabled,_Set,_'1']" 0 "[No,_Off,_Disabled,_Reset,_'0']" 3 "[Unavailable,_Unknown]" ;
VAL_ 2583298814 DGNSSMode 7 "Null" 6 "Error" 5 "Reserved" 4 "RTK_Differential_Corrections" 3 "RTCA_SC159_Network_Corrections" 2 "RTCMSC104PseudorangeCorrections" 1 "Auto" 0 "Off" ;
VAL_ 2583298814 GNSSMode 7 "Null" 6 "Error" 4 "Reserved" 3 "Auto" 2 "3D" 1 "2D" 0 "1D" ;
VAL_ 2583303422 PRN 96 "GLONASSFrGLONASSStlltsArIdntfdBy" 64 "SBASStlltBsdAgmentationSystem65" 1 "GPS,_" 33 "0" 0 "not" ;
VAL_ 2582778366 FluidType 15 "Data_not_available" 14 "Error" 13 "Reserved" 6 "Reserved," 0 "5" 0 "Water" 0 "4" 0 "3" 0 "Well" 2 "Waste" 0 "1" 0 "Water" 0 "Fuel" ;
VAL_ 2582778366 FluidInstance 15 "Instance_number_0_to_15" ;
VAL_ 2516387582 SequenceID_ 255 "nVldPsFxTTItTRng0T250FrVldPstnFx" ;
VAL_ 2515667710 EngInstance 255 "Not_available" 254 "Error" 253 "Reserve" 1 "DlEngStrBrdTStrnStrbrdNInstncNWh" 0 "SingleEngDualEnginePort" ;
VAL_ 2314338558 EngInstance 255 "Not_available" 254 "Error" 253 "Reserve" 1 "DlEngStrBrdTStrnStrbrdNInstncNWh" 0 "SingleEngDualEnginePort" ;
VAL_ 2314338814 EngInstance 255 "Not_available" 254 "Error" 253 "Reserve" 1 "DlEngStrBrdTStrnStrbrdNInstncNWh" 0 "SingleEngDualEnginePort" ;
VAL_ 2582975486 MeasurementTime 0 "midnight,__time_is_in_UTC" ;
VAL_ 2448953086 NavigationalStatus 15 "ntDfndSITURM13711FrMrInfrmation" 14 "reserved_for_future_use" 10 "rsrvdFrFtrAmndmntOfNvgtnlSttsFrS" 8 "under_way_sailing" 7 "engaged_in_fishing" 6 "aground" 5 "moored" 4 "constrained_by_her_draught" 3 "restricted_manoeuvrability" 2 "not_under_command" 1 "at_anchor" 0 "under_way_using_engine" ;
VAL_ 2448953086 AISTransceiverInformation 4 "Own_information_not_broadcast" 3 "Channel_B_VDL_transmission" 5 "Reserved" 2 "Channel_A_VDL_transmission" 1 "Channel_B_VDL_reception" 0 "Channel_A_VDL_reception" ;
VAL_ 2448953086 TimeStamp 63 "PsngSystmIsInprtvSITURM13711FrMr" 62 "ElctrncPsFxngSystmOprtsInEstMde" 61 "PosingSystemIsInManualInputMode" 60 "timeStampNotAvailable" 0 "UTCSecondWhenReportWasGenerated" ;
VAL_ 2448953086 RAIMflag 1 "RAIMInUsSITURM13711FrMrInfrmton" 0 "RAIM_not_in_use_default" ;
VAL_ 2448953086 RepeatIndicator 3 "FnlRTrnsSITURM13711FrMrInfrmton" 2 "Second_retransmission" 1 "First_retransmission" 0 "Default" ;
VAL_ 2650473982 AISTransceiverInformation 4 "Own_information_not_broadcast" 3 "Channel_B_VDL_transmission" 5 "Reserved" 2 "Channel_A_VDL_transmission" 1 "Channel_B_VDL_reception" 0 "Channel_A_VDL_reception" ;
VAL_ 2650473982 RepeatIndicator 3 "FnlRTrnsSITURM13711FrMrInfrmton" 2 "Second_retransmission" 1 "First_retransmission" 0 "Default" ;
VAL_ 2650475774 AISTransceiverInformation 4 "Own_information_not_broadcast" 3 "Channel_B_VDL_transmission" 5 "Reserved" 2 "Channel_A_VDL_transmission" 1 "Channel_B_VDL_reception" 0 "Channel_A_VDL_reception" ;
VAL_ 2650475774 RepeatIndicator 3 "FnlRTrnsSITURM13711FrMrInfrmton" 2 "Second_retransmission" 1 "First_retransmission" 0 "Default" ;
VAL_ 2565406462 ControlByte 3 "CannotRespond" 2 "AccessDenied" 1 "NACK" 0 "ACK" ;
VAL_ 2382238206 SID 255 "nVldPsFxTTItTRng0T250FrVldPstnFx" ;
VAL_ 2382238206 Set_COG_HeadingRef 3 "Null" 2 "Error" 1 "Magnetic" 0 "True" ;
VAL_ 2382238206 DataMode 15 "Data_not_available" 14 "Error" 4 "Manual_mode" 3 "Simulator_mode" 2 "Estimated_mode" 1 "Differential,_enhanced_mode" 0 "Autonomous_mode" ;
VAL_ 2583301630 SatelliteID 96 "GLONASSFrGLONASSStlltsArIdntfdBy" 64 "SBASStlltBsdAgmentationSystem65" 1 "GPS,_" 33 "0" 0 "not" ;
VAL_ 2583301630 StationHealth 21 "Reserved" 4 "InTestModeDONOTUSE0x05" 3 "Healthy_&_in_Test_Mode" 2 "Healthy_&_Operational" 1 "Unmonitored" 0 "Not_Working" ;
VAL_ 2583301630 ReferenceStationType 15 "Null" 14 "Error" 13 "Reserved" 1 "GLONASS_" ;
VAL_ 2583301630 SequenceID_ 255 "nVldPsFxTTItTRng0T250FrVldPstnFx" ;
VAL_ 2583499518 MeasurementTime 0 "midnight,__time_is_in_UTC" ;
VAL_ 2583499518 State 111 "Unavailable,_Unknown" 110 "Error" 101 "Reserved" 10 "Ebb" 1 "Slack" 0 "Flood" ;
VAL_ 2583499518 Mode 15 "Data_not_available" 14 "Error" 4 "Manual_mode" 3 "Simulator_mode" 2 "Estimated_mode" 1 "Differential,_enhanced_mode" 0 "Autonomous_mode" ;
VAL_ 2381906942 NavigationTerminated 3 "[Unavailable,_Unknown]" 2 "Error" 1 "[Yes,_On,_Enabled,_Set,_'1']" 0 "[No,_Off,_Disabled,_Reset,_'0']" ;
VAL_ 2381906942 XTEMode 15 "Data_not_available" 14 "Error" 4 "Manual_mode" 3 "Simulator_mode" 2 "Estimated_mode" 1 "Differential,_enhanced_mode" 0 "Autonomous_mode" ;
VAL_ 2381906942 SID 255 "nVldPsFxTTItTRng0T250FrVldPstnFx" ;
VAL_ 2314732286 COGReference 3 "Null" 2 "Error" 1 "Magnetic" 0 "True" ;
VAL_ 2314732286 SID 255 "nVldPsFxTTItTRng0T250FrVldPstnFx" ;
VAL_ 2650475006 AISTransceiverInformation 4 "Own_information_not_broadcast" 3 "Channel_B_VDL_transmission" 5 "Reserved" 2 "Channel_A_VDL_transmission" 1 "Channel_B_VDL_reception" 0 "Channel_A_VDL_reception" ;
VAL_ 2650475006 RepeatIndicator 3 "FnlRTrnsSITURM13711FrMrInfrmton" 2 "Second_retransmission" 1 "First_retransmission" 0 "Default" ;
VAL_ 2650473470 AISTransceiverInformation 4 "Own_information_not_broadcast" 3 "Channel_B_VDL_transmission" 5 "Reserved" 2 "Channel_A_VDL_transmission" 1 "Channel_B_VDL_reception" 0 "Channel_A_VDL_reception" ;
VAL_ 2650473470 RepeatIndicator 3 "FnlRTrnsSITURM13711FrMrInfrmton" 2 "Second_retransmission" 1 "First_retransmission" 0 "Default" ;
VAL_ 2650473726 AISTransceiverInformation 4 "Own_information_not_broadcast" 3 "Channel_B_VDL_transmission" 5 "Reserved" 2 "Channel_A_VDL_transmission" 1 "Channel_B_VDL_reception" 0 "Channel_A_VDL_reception" ;
VAL_ 2650473726 RepeatIndicator 3 "FnlRTrnsSITURM13711FrMrInfrmton" 2 "Second_retransmission" 1 "First_retransmission" 0 "Default" ;
VAL_ 2582777854 Line 0 "Line1" 1 "Line2" 2 "Line3" 3 "Reserved" ;
VAL_ 2582777854 Acceptability 0 "BadLevel" 1 "BadFrequency" 2 "BeingQualified" 3 "Good" ;
VAL_ 2582778110 Line 0 "Line1" 1 "Line2" 2 "Line3" 3 "Reserved" ;
VAL_ 2582778110 Waveform 0 "SineWave" 1 "ModifiedSineWave" 2 "Reserved" 3 "Reserved" 4 "Reserved" 5 "Reserved" 6 "Error" 7 "DataNotAvailable" ;
VAL_ 2582778622 DC_Type 0 "Battery" 1 "Alternator" 2 "Convertor" 3 "SolarCell" 4 "WindGenerator" 5 "Reserved" ;
VAL_ 2582778878 Operating_State 0 "NotCharging" 1 "Bulk" 2 "Absorption" 3 "Overcharge" 4 "Equalize" 5 "Float" 6 "NoFloat" 7 "ConstantVI" 8 "Disabled" 9 "Fault" 10 "Fault" 11 "Fault" 12 "Fault" 13 "Reserved" 14 "Error" 15 "DataNotAvailable" ;
VAL_ 2582778878 Charge_Mode 0 "StandAlone" 1 "Primary" 2 "Secondary" 3 "Echo" 4 "Reserved" ;
VAL_ 2582778878 Charger_EnableDisable 0 "NoOffDisabledReset0" 1 "YesOnEnabledSet1" 2 "Error" 3 "UnavailableUnknown" ;
VAL_ 2582778878 Equalization_Pending 0 "NoOffDisabledReset0" 1 "YesOnEnabledSet1" 2 "Error" 3 "UnavailableUnknown" ;
VAL_ 2582779390 Operating_State 0 "Invert" 1 "ACPassthru" 2 "LoadSense" 3 "Fault" 4 "Disabled" 5 "Reserved" ;
VAL_ 2582779390 Inverter_EnableDisable 0 "NoOffDisabledReset0" 1 "YesOnEnabledSet1" 2 "Error" 3 "UnavailableUnknown" ;
VAL_ 2582779646 Charger_EnableDisable 0 "TurnOffDisableResetMake0" 1 "TurnOnEnableSetMake1" 2 "Reserved" 3 "NoAction" ;
VAL_ 2582779646 Charging_Algorithm 0 "Trickle" 1 "CVCCConstantVoltageConstantCurrent" 2 "2StageNoFloat" 3 "3Stage" 4 "Reserved" ;
VAL_ 2582779646 Charger_Mode 0 "Standalone" 1 "Primary" 2 "Secondary" 3 "Echo" 4 "Reserved" ;
VAL_ 2582779646 Estimated_Battery_Temp_When_No_S 0 "Cold" 1 "Warm" 2 "Hot" 3 "Reserved" ;
VAL_ 2582779646 Equalize_One_Time_EnableDisable 0 "TurnOffDisableResetMake0" 1 "TurnOnEnableSetMake1" 2 "Reserved" 3 "NoAction" ;
VAL_ 2582779646 Over_Charge_EnableDisable 0 "TurnOffDisableResetMake0" 1 "TurnOnEnableSetMake1" 2 "Reserved" 3 "NoAction" ;
VAL_ 2582779902 Inverter_EnableDisable 0 "TurnOffDisableResetMake0" 1 "TurnOnEnableSetMake1" 2 "Reserved" 3 "NoAction" ;
VAL_ 2582779902 Inverter_Mode 0 "Standalone" 1 "SeriesMaster" 2 "SeriesSlave" 3 "ParallelMaster" 4 "ParallelSlave" 5 "Reserved" ;
VAL_ 2582779902 Load_Sense_EnableDisable 0 "TurnOffDisableResetMake0" 1 "TurnOnEnableSetMake1" 2 "Reserved" 3 "NoAction" ;
VAL_ 2582780158 AGS_Mode 0 "Off" 1 "On" 2 "Automatic" 3 "Reserved" ;
VAL_ 2582780414 Battery_Type 0 "Flooded" 1 "GEL" 2 "AGM" 3 "Reserved" ;
VAL_ 2582780414 Support_Equalization 0 "NoOffDisabledReset0" 1 "YesOnEnabledSet1" 2 "Error" 3 "UnavailableUnknown" ;
VAL_ 2582780414 Nominal_Voltage 0 "6Volts" 1 "12Volts" 2 "24Volts" 3 "32Volts" 4 "36Volts" 5 "42Volts" 6 "48Volts" 7 "Reserved" ;
VAL_ 2582780414 Battery_Chemistry 0 "LeadAcid" 1 "LiIon" 2 "NiCad" 3 "ZnO" 4 "NiMH" 5 "Reserved" ;
VAL_ 2582780670 AGS_Operating_State 0 "QuietTime" 1 "AutoOn" 2 "AutoOff" 3 "ManualOn" 4 "ManualOff" 5 "GeneratorShutdown" 6 "ExternalShutdown" 7 "Fault" 8 "Suspend" 9 "NotOperating" 10 "Reserved" ;
VAL_ 2582780670 Generator_State 0 "Preheating" 1 "StartDelay" 2 "Cranking" 3 "StarterCooling" 4 "WarmingUp" 5 "CollingDown" 6 "SpinningDown" 7 "ShutdownBypass" 8 "Stopping" 9 "Running" 10 "Stopped" 11 "CrankDelay" 12 "Reserved" ;
VAL_ 2582780670 Generator_On_Reason 0 "NotOn" 1 "DCVoltageLow" 2 "BatteryStateOfChargeLow" 3 "ACCurrentHigh" 4 "ContactClosed" 5 "ManualOn" 6 "Exercise" 7 "NonQuietTime" 8 "ExternalOnViaAGS" 9 "ExternalOnViaGenerator" 10 "UnableToStop" 11 "Reserved" ;
VAL_ 2582780670 GeneratorOffReason 0 "NotOff" 1 "DCVoltageHigh" 2 "BatteryStateOfChargeHigh" 3 "ACCurrentLow" 4 "ContactOpened" 5 "ReachedAbsorption" 6 "ReachedFloat" 7 "ManualOff" 8 "MaxRunTime" 9 "MaxAutoCycle" 10 "ExerciseDone" 11 "QuietTime" 12 "ExternalOffViaAGS" 13 "SafeMode" 14 "ExternalOffViaGenerator" 15 "ExternalShutdown" 16 "AutoOff" 17 "Fault" 18 "UnableToStart" 19 "Reserved" ;
VAL_ 2650476286 Repeat_Indicator 0 "Default" 1 "FirstRestransmission" 2 "SecondRestransmission" 3 "FinalRetransmission" ;
VAL_ 2650476286 AIS_Transceiver_Information 0 "ChannelAVDLreception" 1 "ChannelBVDLreception" 2 "ChannelAVDLtransmission" 3 "ChannelBVDLtransmission" 4 "Owninformationnotbroadcast" ;
VAL_ 2650476286 Power 0 "HighDefault" 1 "Low" ;
VAL_ 2650476286 TxRx_Mode 0 "TxATxBRxARxBdefault" 1 "TxARxARxB" 2 "TxBRxARx1" ;
VAL_ 2650476286 Addressed_or_Broadcast_Message_I 0 "BroadcastGeographicalAreaMessage" 1 "AddressedMessage" ;
VAL_ 2650476286 Channel_A_Bandwidth 0 "default" 0 "12500HzBandwidth" ;
VAL_ 2650476286 Channel_B_Bandwidth 0 "default" 1 "12500HzBandwidth" ;
VAL_ 2650476542 Repeat_Indicator 0 "Default" 1 "FirstRestransmission" 2 "SecondRetransmission" 3 "FinalRetransmission" ;
VAL_ 2650476542 TxRx_Mode 0 "TxATxBRxARxBdefault" 1 "TxARxARxB" 2 "TxBRxARxB" ;
VAL_ 2650476542 Station_Type 0 "Alltypesofmobilesdefault" 1 "Reservedforfutureuse" 2 "AlltypesofClassBmobilestations" 3 "SARairbornemobilestation" 4 "AtoNstation" 5 "ClassBCSshipbornemobilestationonly" 6 "Inlandwaterways" ;
VAL_ 2650476542 Ship_and_Cargo_Filter 0 "alltypes" 1 "SeeITURM1371Table50" ;
VAL_ 2650476542 Reporting_Interval 0 "AsGivenByTheAutonomousMode" 1 "10min" 2 "6min" 3 "3min" 4 "1min" 5 "30sec" 6 "15sec" 7 "10sec" 8 "5sec" 9 "2sec" 10 "NextShorterReportingInterval" 11 "NextLongerReportingInterval" ;
VAL_ 2650476542 Quiet_Time 0 "NoQuietTimeCommanded" 1 "QuietTimeOf1min" 2 "QuietTimeOf2min" 3 "QuietTimeOf3min" 4 "QuietTimeOf4min" 5 "QuietTimeOf5min" 6 "QuietTimeOf6min" 7 "QuietTimeOf7min" 8 "QuietTimeOf8min" 9 "QuietTimeOf9min" 10 "QuietTimeOf10min" 11 "QuietTimeOf11min" 12 "QuietTimeOf12min" 13 "QuietTimeOf13min" 14 "QuietTimeOf14min" 15 "QuietTimeOf15min" ;
VAL_ 2583368190 Repeat_Indicator 0 "Default" 1 "FirstRetransmission" 2 "SecondRetransmission" 3 "FinalRetransmission" ;
VAL_ 2583368446 Repeat_Indicator 0 "Default" 1 "FirstRetransmission" 2 "SecondRetransmission" 3 "FinalRetransmission" ;
VAL_ 2583368446 Type_Of_Ship_And_Cargo 0 "NotAvailableOrNoShipDefault" 1 "ITURM1371Section338232Table18" ;
VAL_ 2516388094 Temperature_Instance 0 "Instance0" 1 "Instance1" ;
VAL_ 2516388094 Temperature_Source 0 "SeaTemperature" 1 "OutsideTemperature" 2 "InsideTemperature" 3 "EngineRoomTemperature" 4 "MainCabinTemperature" 5 "LiveWellTemperature" 6 "BaitWellTemperature" 7 "RefrigerationTemperature" 8 "HeatingSystemTemperature" 9 "DewPointTemperature" 10 "WindChillTemperatureApparent" 11 "WindChillTemperatureTheorical" 12 "HeatIndexTemperature" 13 "FreezerTemperature" ;
VAL_ 2516388350 Humidity_Instance 0 "Instance0" 1 "Instance1" ;
VAL_ 2516388350 Humidity_Source 0 "InsideHumidity" 1 "OutsideHumidity" 2 "Reserved" ;
VAL_ 2516388606 Pressure_Instance 0 "Instance0" 1 "Instance1" ;
VAL_ 2516388606 Pressure_Source 0 "AtmosphericPressure" 1 "WaterPressure" 2 "SteamPressure" 3 "CompressedAirPressure" 4 "HydraulicPressure" ;
VAL_ 2516388862 Pressure_Instance 0 "Instance0" 1 "Instance1" ;
VAL_ 2516388862 Pressure_Source 0 "AtmosphericPressure" 1 "WaterPressure" 2 "SteamPressure" 3 "CompressedAirPressure" 4 "HydraulicPressure" ;
VAL_ 2516387838 HumidityInstance 3 "Data_Not_Available" 2 "reserved" 1 "Outside_Humidity" 0 "Inside_Humidity" ;
VAL_ 2516387838 TempInstance 63 "Data_Not_Available" 62 "Reserve" 5 "Reserve," 0 "4" 0 "Cabin" 0 "3" 0 "Room" 0 "2" 0 "Temperature" 1 "Outside" 0 "0" 0 "Temperature" ;
VAL_ 2516387838 SequenceID_ 255 "nVldPsFxTTItTRng0T250FrVldPstnFx" ;
VAL_ 2582576894 GrpFnctnTrnsmtAndReceivePGNList 1 "Receive_PGN_List_Message" 0 "Transmit_PGN_List_Message" ;
